AUTOSAR XML (schema 4-1-3)
standard types defined: boolean, sint8, uint16, uint32, uint8, boolean_CompuMethod, boolean_DataConstr, sint8_DataConstr, uint16_DataConstr, uint32_DataConstr, uint8_DataConstr, sint16, sint32
package /MICROSAR/Dem_swc/DataTypes
  5 x impl type:
    Dem_DebounceResetStatusType: compu {0=DEM_DEBOUNCE_STATUS_FREEZE, 1=DEM_DEBOUNCE_STATUS_RESET}, range raw 0..255, implementation-data-type=ImplementationDataTypes/uint8
    Dem_DTCFormatType: compu {0=DEM_DTC_FORMAT_OBD, 1=DEM_DTC_FORMAT_UDS, 2=DEM_DTC_FORMAT_J1939}, range raw 0..2, implementation-data-type=ImplementationDataTypes/uint8
    Dem_EventStatusType:
      compu {0=DEM_EVENT_STATUS_PASSED, 1=DEM_EVENT_STATUS_FAILED, 2=DEM_EVENT_STATUS_PREPASSED, 3=DEM_EVENT_STATUS_PREFAILED, 4=DEM_EVENT_STATUS_FDC_THRESHOLD_REACHED, 5=DEM_EVENT_STATUS_PASSED_CONDITIONS_NOT_FULFILLED, 6=DEM_EVENT_STATUS_FAILED_CONDITIONS_NOT_FULFILLED, 7=DEM_EVENT_STATUS_PREPASSED_CONDITIONS_NOT_FULFILLED, 8=DEM_EVENT_STATUS_PREFAILED_CONDITIONS_NOT_FULFILLED}
      range raw 0..255
      implementation-data-type=ImplementationDataTypes/uint8
    Dem_MaxDataValueType: category=ARRAY, sw-calibration-access=READ-ONLY
      element Dem_MaxDataValueTypeElement: array-size=16, array-size-semantics=FIXED-SIZE, implementation-data-type=ImplementationDataTypes/uint8
    Dem_UdsStatusByteType:
      compu {mask 1: 1=DEM_UDS_STATUS_TF (bit 0: TestFailed), mask 2: 2=DEM_UDS_STATUS_TFTOC (bit 1: TestFailedThisOperationCycle), mask 4: 4=DEM_UDS_STATUS_PDTC (bit 2: PendingDTC), mask 8: 8=DEM_UDS_STATUS_CDTC (bit 3: ConfirmedDTC), mask 16: 16=DEM_UDS_STATUS_TNCSLC (bit 4: TestNotCompletedSinceLastClear), mask 32: 32=DEM_UDS_STATUS_TFSLC (bit 5: TestFailedSinceLastClear), mask 64: 64=DEM_UDS_STATUS_TNCTOC (bit 6: TestNotCompletedThisOperationCycle), mask 128: 128=DEM_UDS_STATUS_WIR (bit 7: WarningIndicatorRequested)}
      range raw 0..255
      implementation-data-type=ImplementationDataTypes/uint8
package /MICROSAR/Dem_swc/Interfaces
  client server interface DiagnosticMonitor: is-service=true, service-kind=DIAGNOSTIC-EVENT-MANAGER
    11 x operation:
      GetDTCOfEvent: possible-error=[DEM_E_NO_DTC_AVAILABLE, DiagnosticMonitor/E_NOT_OK]
        arg DTCFormat: type=Dem_DTCFormatType, direction=IN, server-argument-impl-policy=USE-ARGUMENT-TYPE
        arg DTCOfEvent: type=ImplementationDataTypes/uint32, direction=OUT, server-argument-impl-policy=USE-ARGUMENT-TYPE
      GetEventExtendedDataRecordEx: possible-error=[DEM_BUFFER_TOO_SMALL, DEM_NO_SUCH_ELEMENT, DiagnosticMonitor/E_NOT_OK]
        arg RecordNumber: type=ImplementationDataTypes/uint8, direction=IN, server-argument-impl-policy=USE-ARGUMENT-TYPE
        arg DestBuffer: type=Dem_MaxDataValueType, direction=OUT, server-argument-impl-policy=USE-ARGUMENT-TYPE
        arg BufSize: type=ImplementationDataTypes/uint16, direction=INOUT, server-argument-impl-policy=USE-ARGUMENT-TYPE
      GetEventFailed: possible-error=DiagnosticMonitor/E_NOT_OK
        arg EventFailed: type=ImplementationDataTypes/boolean, direction=OUT, server-argument-impl-policy=USE-ARGUMENT-TYPE
      GetEventFreezeFrameDataEx: possible-error=[DEM_BUFFER_TOO_SMALL, DEM_NO_SUCH_ELEMENT, DiagnosticMonitor/E_NOT_OK]
        4 x arg, all with server-argument-impl-policy=USE-ARGUMENT-TYPE:
          RecordNumber: type=ImplementationDataTypes/uint8, direction=IN
          DataId: type=ImplementationDataTypes/uint16, direction=IN
          DestBuffer: type=Dem_MaxDataValueType, direction=OUT
          BufSize: type=ImplementationDataTypes/uint16, direction=INOUT
      GetEventStatus: possible-error=DiagnosticMonitor/E_NOT_OK
        arg UDSStatusByte: type=Dem_UdsStatusByteType, direction=OUT, server-argument-impl-policy=USE-ARGUMENT-TYPE
      GetEventTested: possible-error=DiagnosticMonitor/E_NOT_OK
        arg EventTested: type=ImplementationDataTypes/boolean, direction=OUT, server-argument-impl-policy=USE-ARGUMENT-TYPE
      GetEventUdsStatus: possible-error=DiagnosticMonitor/E_NOT_OK
        arg UDSStatusByte: type=Dem_UdsStatusByteType, direction=OUT, server-argument-impl-policy=USE-ARGUMENT-TYPE
      GetFaultDetectionCounter: possible-error=[DEM_E_NO_FDC_AVAILABLE, DiagnosticMonitor/E_NOT_OK]
        arg FaultDetectionCounter: type=sint8, direction=OUT, server-argument-impl-policy=USE-ARGUMENT-TYPE
      ResetEventDebounceStatus: possible-error=DiagnosticMonitor/E_NOT_OK
        arg DebounceResetStatus: type=Dem_DebounceResetStatusType, direction=IN, server-argument-impl-policy=USE-ARGUMENT-TYPE
      ResetEventStatus: possible-error=DiagnosticMonitor/E_NOT_OK
      SetEventStatus: possible-error=DiagnosticMonitor/E_NOT_OK
        arg EventStatus: type=Dem_EventStatusType, direction=IN, server-argument-impl-policy=USE-ARGUMENT-TYPE
    5 x error:
      DEM_BUFFER_TOO_SMALL: error-code=21
      DEM_E_NO_DTC_AVAILABLE: error-code=10
      DEM_E_NO_FDC_AVAILABLE: error-code=14
      DEM_NO_SUCH_ELEMENT: error-code=48
      E_NOT_OK: error-code=1
package /SwAddrMethods
  sw addr method CALDATA
package /UAES/ASW/ApplicationDataTypes
  app type Curr_Ampr_u16: category=VALUE, sw-calibration-access=READ-WRITE, compu {phys=raw*0.1; unit A}, range raw 0..65535, unit=A
  app type q1Em6_s_S32: category=VALUE, sw-calibration-access=READ-WRITE, compu {phys=raw*1e-06}, range phys -2147.483648..2147.483647, raw -2147483648..2147483647
package /UAES/ASW/CompuMethods
  compu method CM_boolean: 0=FALSE, 1=TRUE
package /UAES/ASW/DataConstrs
  range DC_sint16: raw -32768..32767
package /UAES/ASW/DataTypeMappingSets
  data type mapping set DTMS_FaultDiag
    data-type-maps:
      application-data-type=Curr_Ampr_u16, implementation-data-type=ImplementationDataTypes/uint16
      application-data-type=q1Em6_s_S32, implementation-data-type=sint32
package /UAES/ASW/ImplementationDataTypes
  4 x impl type, all with category=ARRAY:
    rt_Array_boolean_29
      element rt_Array_boolean_29: array-size=29, array-size-semantics=FIXED-SIZE, implementation-data-type=ImplementationDataTypes/boolean
    rt_Array_uint16_25
      element rt_Array_uint16_25: array-size=25, array-size-semantics=FIXED-SIZE, implementation-data-type=ImplementationDataTypes/uint16
    rt_Array_uint16_29
      element rt_Array_uint16_29: array-size=29, array-size-semantics=FIXED-SIZE, implementation-data-type=ImplementationDataTypes/uint16
    rt_Array_uint8_29
      element rt_Array_uint8_29: array-size=29, array-size-semantics=FIXED-SIZE, implementation-data-type=ImplementationDataTypes/uint8
package /UAES/ASW/PortInterfaces
  7 x client server interface:
    IoHwAb_IoDiagDo
      operation Do_Get: possible-error=IoHwAb_IoDiagDo/E_NOT_OK
        arg id_u16: type=ImplementationDataTypes/uint16, direction=IN, server-argument-impl-policy=USE-ARGUMENT-TYPE
        arg val_u32: type=ImplementationDataTypes/uint32, direction=OUT, server-argument-impl-policy=USE-ARGUMENT-TYPE
      error E_NOT_OK: error-code=1
    IoHwAb_IoDiagPwm
      operation Pwm_Get: possible-error=IoHwAb_IoDiagPwm/E_NOT_OK
        arg id_u16: type=ImplementationDataTypes/uint16, direction=IN, server-argument-impl-policy=USE-ARGUMENT-TYPE
        arg val_u32: type=ImplementationDataTypes/uint32, direction=OUT, server-argument-impl-policy=USE-ARGUMENT-TYPE
      error E_NOT_OK: error-code=1
    IoHwAb_IoSigAdc
      operation Adc_Get: possible-error=IoHwAb_IoSigAdc/E_NOT_OK
        arg id_u16: type=ImplementationDataTypes/uint16, direction=IN, server-argument-impl-policy=USE-ARGUMENT-TYPE
        arg val_s16: type=sint16, direction=OUT, server-argument-impl-policy=USE-ARGUMENT-TYPE
      operation AdcFac_Get: possible-error=IoHwAb_IoSigAdc/E_NOT_OK
        arg id_u16: type=ImplementationDataTypes/uint16, direction=IN, server-argument-impl-policy=USE-ARGUMENT-TYPE
        arg val_s16: type=sint16, direction=OUT, server-argument-impl-policy=USE-ARGUMENT-TYPE
      operation AdcVRMBatt_Get: possible-error=IoHwAb_IoSigAdc/E_NOT_OK
        arg id_u16: type=ImplementationDataTypes/uint16, direction=IN, server-argument-impl-policy=USE-ARGUMENT-TYPE
        arg val_u8: type=ImplementationDataTypes/uint8, direction=OUT, server-argument-impl-policy=USE-ARGUMENT-TYPE
      error E_NOT_OK: error-code=1
    IoHwAb_IoSigDio
      operation Di_Get: possible-error=IoHwAb_IoSigDio/E_NOT_OK
        arg id_u16: type=ImplementationDataTypes/uint16, direction=IN, server-argument-impl-policy=USE-ARGUMENT-TYPE
        arg val_u8: type=ImplementationDataTypes/uint8, direction=OUT, server-argument-impl-policy=USE-ARGUMENT-TYPE
      operation Do_Set: possible-error=IoHwAb_IoSigDio/E_NOT_OK
        arg id_u16: type=ImplementationDataTypes/uint16, direction=IN, server-argument-impl-policy=USE-ARGUMENT-TYPE
        arg val_u8: type=ImplementationDataTypes/uint8, direction=IN, server-argument-impl-policy=USE-ARGUMENT-TYPE
      error E_NOT_OK: error-code=1
    IoHwAb_IoSigPwm
      operation Pwm_SetDuty: possible-error=IoHwAb_IoSigPwm/E_NOT_OK
        arg id_u16: type=ImplementationDataTypes/uint16, direction=IN, server-argument-impl-policy=USE-ARGUMENT-TYPE
        arg duty_u16: type=ImplementationDataTypes/uint16, direction=IN, server-argument-impl-policy=USE-ARGUMENT-TYPE
      operation Pwm_SetPerd: possible-error=IoHwAb_IoSigPwm/E_NOT_OK
        arg id_u16: type=ImplementationDataTypes/uint16, direction=IN, server-argument-impl-policy=USE-ARGUMENT-TYPE
        arg perd_u32: type=ImplementationDataTypes/uint32, direction=IN, server-argument-impl-policy=USE-ARGUMENT-TYPE
      operation Pwm_SetPerdAndDuty: possible-error=IoHwAb_IoSigPwm/E_NOT_OK
        arg id_u16: type=ImplementationDataTypes/uint16, direction=IN, server-argument-impl-policy=USE-ARGUMENT-TYPE
        arg perd_u32: type=ImplementationDataTypes/uint32, direction=IN, server-argument-impl-policy=USE-ARGUMENT-TYPE
        arg duty_u16: type=ImplementationDataTypes/uint16, direction=IN, server-argument-impl-policy=USE-ARGUMENT-TYPE
      error E_NOT_OK: error-code=1
    NMW_tGetAllCurrentComModeRTE
      operation Operation: possible-error=NMW_tGetAllCurrentComModeRTE/NmChannelIndexError
        arg Status: type=ImplementationDataTypes/boolean, direction=OUT, server-argument-impl-policy=USE-ARGUMENT-TYPE
      error NmChannelIndexError: error-code=1
    NMW_tGetCurrentComModeRTE
      operation Operation: possible-error=NMW_tGetCurrentComModeRTE/NmChannelIndexError
        arg ComMChannel: type=ImplementationDataTypes/uint8, direction=IN, server-argument-impl-policy=USE-ARGUMENT-TYPE
        arg ChannelStatus: type=ImplementationDataTypes/boolean, direction=OUT, server-argument-impl-policy=USE-ARGUMENT-TYPE
      error NmChannelIndexError: error-code=1
  57 x sender receiver interface:
    BattU_bVoltEnbPinDiag: invalidation-policy{data-element=BattU_bVoltEnbPinDiag/Val, handle-invalid=DONT-INVALIDATE}
      data Val: sw-calibration-access=READ-ONLY, range raw 0..1, type=ImplementationDataTypes/boolean
    gKL15PwrSply_u32AllowSleep_Local: invalidation-policy{data-element=gKL15PwrSply_u32AllowSleep_Local/Val, handle-invalid=DONT-INVALIDATE}
      data Val: sw-calibration-access=READ-ONLY, range raw 0..4294967295, type=ImplementationDataTypes/uint32
    gKL15PwrSply_u32AllowSleep_NW: invalidation-policy{data-element=gKL15PwrSply_u32AllowSleep_NW/Val, handle-invalid=DONT-INVALIDATE}
      data Val: sw-calibration-access=READ-ONLY, range raw 0..4294967295, type=ImplementationDataTypes/uint32
    gKL15PwrSply_u8Wakeup: invalidation-policy{data-element=gKL15PwrSply_u8Wakeup/Val, handle-invalid=DONT-INVALIDATE}
      data Val: sw-calibration-access=READ-ONLY, range raw 0..255, type=ImplementationDataTypes/uint8
    gPRM_au16OvrCurrDebTime: invalidation-policy{data-element=gPRM_au16OvrCurrDebTime/Val, handle-invalid=DONT-INVALIDATE}
      data Val: sw-calibration-access=READ-ONLY, range raw 0..65535, type=rt_Array_uint16_25
    gPRM_au16OvrCurrThres: invalidation-policy{data-element=gPRM_au16OvrCurrThres/Val, handle-invalid=DONT-INVALIDATE}
      data Val: sw-calibration-access=READ-ONLY, range raw 0..65535, type=rt_Array_uint16_25
    gPRM_u8VehRLCM: invalidation-policy{data-element=gPRM_u8VehRLCM/Val, handle-invalid=DONT-INVALIDATE}
      data Val: sw-calibration-access=READ-ONLY, range raw 0..255, type=ImplementationDataTypes/uint8
    gVRM_u16BatteryVolt_mv: invalidation-policy{data-element=gVRM_u16BatteryVolt_mv/Val, handle-invalid=DONT-INVALIDATE}
      data Val: sw-calibration-access=READ-ONLY, type=ImplementationDataTypes/uint16
    KL15PwrSply_bAMPPowerTrigUds: invalidation-policy{data-element=KL15PwrSply_bAMPPowerTrigUds/Val, handle-invalid=DONT-INVALIDATE}
      data Val: sw-calibration-access=READ-ONLY, range raw 0..1, type=ImplementationDataTypes/boolean
    KL15PwrSply_bInverterPowerTrigUds: invalidation-policy{data-element=KL15PwrSply_bInverterPowerTrigUds/Val, handle-invalid=DONT-INVALIDATE}
      data Val: sw-calibration-access=READ-ONLY, range raw 0..1, type=ImplementationDataTypes/boolean
    KL15PwrSply_bKL15T1PowerTrigUds: invalidation-policy{data-element=KL15PwrSply_bKL15T1PowerTrigUds/Val, handle-invalid=DONT-INVALIDATE}
      data Val: sw-calibration-access=READ-ONLY, range raw 0..1, type=ImplementationDataTypes/boolean
    KL15PwrSply_bKL15T2PowerTrigUds: invalidation-policy{data-element=KL15PwrSply_bKL15T2PowerTrigUds/Val, handle-invalid=DONT-INVALIDATE}
      data Val: sw-calibration-access=READ-ONLY, range raw 0..1, type=ImplementationDataTypes/boolean
    KL15PwrSply_bPCUPowerTrigUds: invalidation-policy{data-element=KL15PwrSply_bPCUPowerTrigUds/Val, handle-invalid=DONT-INVALIDATE}
      data Val: sw-calibration-access=READ-ONLY, range raw 0..1, type=ImplementationDataTypes/boolean
    KL15PwrSply_bRear12VPowerTrigUds: invalidation-policy{data-element=KL15PwrSply_bRear12VPowerTrigUds/Val, handle-invalid=DONT-INVALIDATE}
      data Val: sw-calibration-access=READ-ONLY, range raw 0..1, type=ImplementationDataTypes/boolean
    KL15PwrSply_bRearBlowerPowerTrigUds: invalidation-policy{data-element=KL15PwrSply_bRearBlowerPowerTrigUds/Val, handle-invalid=DONT-INVALIDATE}
      data Val: sw-calibration-access=READ-ONLY, range raw 0..1, type=ImplementationDataTypes/boolean
    KL15PwrSply_bRearCtrlPanelPowerTrigUds: invalidation-policy{data-element=KL15PwrSply_bRearCtrlPanelPowerTrigUds/Val, handle-invalid=DONT-INVALIDATE}
      data Val: sw-calibration-access=READ-ONLY, range raw 0..1, type=ImplementationDataTypes/boolean
    KL15PwrSply_bRearEOPPowerTrigUds: invalidation-policy{data-element=KL15PwrSply_bRearEOPPowerTrigUds/Val, handle-invalid=DONT-INVALIDATE}
      data Val: sw-calibration-access=READ-ONLY, range raw 0..1, type=ImplementationDataTypes/boolean
    KL15PwrSply_bRearMotorPowerTrigUds: invalidation-policy{data-element=KL15PwrSply_bRearMotorPowerTrigUds/Val, handle-invalid=DONT-INVALIDATE}
      data Val: sw-calibration-access=READ-ONLY, range raw 0..1, type=ImplementationDataTypes/boolean
    KL15PwrSply_bRearRadarPowerTrigUds: invalidation-policy{data-element=KL15PwrSply_bRearRadarPowerTrigUds/Val, handle-invalid=DONT-INVALIDATE}
      data Val: sw-calibration-access=READ-ONLY, range raw 0..1, type=ImplementationDataTypes/boolean
    KL15PwrSply_bRLALampCtlUnitPowerTrigUds: invalidation-policy{data-element=KL15PwrSply_bRLALampCtlUnitPowerTrigUds/Val, handle-invalid=DONT-INVALIDATE}
      data Val: sw-calibration-access=READ-ONLY, range raw 0..1, type=ImplementationDataTypes/boolean
    KL15PwrSply_bRLBLampCtlUnitPowerTrigUds: invalidation-policy{data-element=KL15PwrSply_bRLBLampCtlUnitPowerTrigUds/Val, handle-invalid=DONT-INVALIDATE}
      data Val: sw-calibration-access=READ-ONLY, range raw 0..1, type=ImplementationDataTypes/boolean
    KL15PwrSply_bRMPowerTrigUds: invalidation-policy{data-element=KL15PwrSply_bRMPowerTrigUds/Val, handle-invalid=DONT-INVALIDATE}
      data Val: sw-calibration-access=READ-ONLY, range raw 0..1, type=ImplementationDataTypes/boolean
    KL15PwrSply_bRRALampCtlUnitPowerTrigUds: invalidation-policy{data-element=KL15PwrSply_bRRALampCtlUnitPowerTrigUds/Val, handle-invalid=DONT-INVALIDATE}
      data Val: sw-calibration-access=READ-ONLY, range raw 0..1, type=ImplementationDataTypes/boolean
    KL15PwrSply_bRRBLampCtlUnitPowerTrigUds: invalidation-policy{data-element=KL15PwrSply_bRRBLampCtlUnitPowerTrigUds/Val, handle-invalid=DONT-INVALIDATE}
      data Val: sw-calibration-access=READ-ONLY, range raw 0..1, type=ImplementationDataTypes/boolean
    KL15PwrSply_u8stAMPPowerUds: invalidation-policy{data-element=KL15PwrSply_u8stAMPPowerUds/Val, handle-invalid=DONT-INVALIDATE}
      data Val: sw-calibration-access=READ-ONLY, range raw 0..255, type=ImplementationDataTypes/uint8
    KL15PwrSply_u8stInverterPowerUds: invalidation-policy{data-element=KL15PwrSply_u8stInverterPowerUds/Val, handle-invalid=DONT-INVALIDATE}
      data Val: sw-calibration-access=READ-ONLY, range raw 0..255, type=ImplementationDataTypes/uint8
    KL15PwrSply_u8stKL15T1PowerUds: invalidation-policy{data-element=KL15PwrSply_u8stKL15T1PowerUds/Val, handle-invalid=DONT-INVALIDATE}
      data Val: sw-calibration-access=READ-ONLY, range raw 0..255, type=ImplementationDataTypes/uint8
    KL15PwrSply_u8stKL15T2PowerUds: invalidation-policy{data-element=KL15PwrSply_u8stKL15T2PowerUds/Val, handle-invalid=DONT-INVALIDATE}
      data Val: sw-calibration-access=READ-ONLY, range raw 0..255, type=ImplementationDataTypes/uint8
    KL15PwrSply_u8stPCUPowerUds: invalidation-policy{data-element=KL15PwrSply_u8stPCUPowerUds/Val, handle-invalid=DONT-INVALIDATE}
      data Val: sw-calibration-access=READ-ONLY, range raw 0..255, type=ImplementationDataTypes/uint8
    KL15PwrSply_u8stRear12VPowerUds: invalidation-policy{data-element=KL15PwrSply_u8stRear12VPowerUds/Val, handle-invalid=DONT-INVALIDATE}
      data Val: sw-calibration-access=READ-ONLY, range raw 0..255, type=ImplementationDataTypes/uint8
    KL15PwrSply_u8stRearBlowerPowerUds: invalidation-policy{data-element=KL15PwrSply_u8stRearBlowerPowerUds/Val, handle-invalid=DONT-INVALIDATE}
      data Val: sw-calibration-access=READ-ONLY, range raw 0..255, type=ImplementationDataTypes/uint8
    KL15PwrSply_u8stRearCtrlPanelPowerUds: invalidation-policy{data-element=KL15PwrSply_u8stRearCtrlPanelPowerUds/Val, handle-invalid=DONT-INVALIDATE}
      data Val: sw-calibration-access=READ-ONLY, range raw 0..255, type=ImplementationDataTypes/uint8
    KL15PwrSply_u8stRearEOPPowerUds: invalidation-policy{data-element=KL15PwrSply_u8stRearEOPPowerUds/Val, handle-invalid=DONT-INVALIDATE}
      data Val: sw-calibration-access=READ-ONLY, range raw 0..255, type=ImplementationDataTypes/uint8
    KL15PwrSply_u8stRearMotorPowerUds: invalidation-policy{data-element=KL15PwrSply_u8stRearMotorPowerUds/Val, handle-invalid=DONT-INVALIDATE}
      data Val: sw-calibration-access=READ-ONLY, range raw 0..255, type=ImplementationDataTypes/uint8
    KL15PwrSply_u8stRearRadarPowerUds: invalidation-policy{data-element=KL15PwrSply_u8stRearRadarPowerUds/Val, handle-invalid=DONT-INVALIDATE}
      data Val: sw-calibration-access=READ-ONLY, range raw 0..255, type=ImplementationDataTypes/uint8
    KL15PwrSply_u8stRLALampCtlUnitPowerUds: invalidation-policy{data-element=KL15PwrSply_u8stRLALampCtlUnitPowerUds/Val, handle-invalid=DONT-INVALIDATE}
      data Val: sw-calibration-access=READ-ONLY, range raw 0..255, type=ImplementationDataTypes/uint8
    KL15PwrSply_u8stRLBLampCtlUnitPowerUds: invalidation-policy{data-element=KL15PwrSply_u8stRLBLampCtlUnitPowerUds/Val, handle-invalid=DONT-INVALIDATE}
      data Val: sw-calibration-access=READ-ONLY, range raw 0..255, type=ImplementationDataTypes/uint8
    KL15PwrSply_u8stRMPowerUds: invalidation-policy{data-element=KL15PwrSply_u8stRMPowerUds/Val, handle-invalid=DONT-INVALIDATE}
      data Val: sw-calibration-access=READ-ONLY, range raw 0..255, type=ImplementationDataTypes/uint8
    KL15PwrSply_u8stRRALampCtlUnitPowerUds: invalidation-policy{data-element=KL15PwrSply_u8stRRALampCtlUnitPowerUds/Val, handle-invalid=DONT-INVALIDATE}
      data Val: sw-calibration-access=READ-ONLY, range raw 0..255, type=ImplementationDataTypes/uint8
    KL15PwrSply_u8stRRBLampCtlUnitPowerUds: invalidation-policy{data-element=KL15PwrSply_u8stRRBLampCtlUnitPowerUds/Val, handle-invalid=DONT-INVALIDATE}
      data Val: sw-calibration-access=READ-ONLY, range raw 0..255, type=ImplementationDataTypes/uint8
    OilPmp_stReqIn: invalidation-policy{data-element=OilPmp_stReqIn/Val, handle-invalid=DONT-INVALIDATE}
      data Val: sw-calibration-access=READ-ONLY, type=ImplementationDataTypes/uint8
    PwrSply_abPwrSt: invalidation-policy{data-element=PwrSply_abPwrSt/Val, handle-invalid=DONT-INVALIDATE}
      data Val: sw-calibration-access=READ-ONLY, range raw 0..1, type=rt_Array_boolean_29
    PwrSply_au16PwrCurr: invalidation-policy{data-element=PwrSply_au16PwrCurr/Val, handle-invalid=DONT-INVALIDATE}
      data Val: sw-calibration-access=READ-ONLY, range raw 0..65535, type=rt_Array_uint16_29
    PwrSply_au8CoornReq: invalidation-policy{data-element=PwrSply_au8CoornReq/Val, handle-invalid=DONT-INVALIDATE}
      data Val: sw-calibration-access=READ-ONLY, type=rt_Array_uint8_29
    PwrSply_au8PwrFaultSt: invalidation-policy{data-element=PwrSply_au8PwrFaultSt/Val, handle-invalid=DONT-INVALIDATE}
      data Val: sw-calibration-access=READ-ONLY, type=rt_Array_uint8_29
    PwrSply_au8PwrSup: invalidation-policy{data-element=PwrSply_au8PwrSup/Val, handle-invalid=DONT-INVALIDATE}
      data Val: sw-calibration-access=READ-ONLY, type=rt_Array_uint8_29
    PwrSply_bCCULostComm: invalidation-policy{data-element=PwrSply_bCCULostComm/Val, handle-invalid=DONT-INVALIDATE}
      data Val: sw-calibration-access=READ-ONLY, range raw 0..1, type=ImplementationDataTypes/boolean
    PwrSply_bNetSleepFlag: invalidation-policy{data-element=PwrSply_bNetSleepFlag/Val, handle-invalid=DONT-INVALIDATE}
      data Val: sw-calibration-access=READ-ONLY, range raw 0..1, type=ImplementationDataTypes/boolean
    PwrSply_bPositionLightCtrlCmd01: invalidation-policy{data-element=PwrSply_bPositionLightCtrlCmd01/Val, handle-invalid=DONT-INVALIDATE}
      data Val: sw-calibration-access=READ-ONLY, type=ImplementationDataTypes/boolean
    PwrSply_bPositionLightCtrlCmd02: invalidation-policy{data-element=PwrSply_bPositionLightCtrlCmd02/Val, handle-invalid=DONT-INVALIDATE}
      data Val: sw-calibration-access=READ-ONLY, type=ImplementationDataTypes/boolean
    PwrSply_bPositionLightCtrlCmd03: invalidation-policy{data-element=PwrSply_bPositionLightCtrlCmd03/Val, handle-invalid=DONT-INVALIDATE}
      data Val: sw-calibration-access=READ-ONLY, type=ImplementationDataTypes/boolean
    PwrSply_bPositionLightCtrlCmd04: invalidation-policy{data-element=PwrSply_bPositionLightCtrlCmd04/Val, handle-invalid=DONT-INVALIDATE}
      data Val: sw-calibration-access=READ-ONLY, type=ImplementationDataTypes/boolean
    PwrSply_bPositionLightTimingOFFEnableCfg: invalidation-policy{data-element=PwrSply_bPositionLightTimingOFFEnableCfg/Val, handle-invalid=DONT-INVALIDATE}
      data Val: sw-calibration-access=READ-ONLY, type=ImplementationDataTypes/boolean
    PwrSply_bVehSpdTkOvr: invalidation-policy{data-element=PwrSply_bVehSpdTkOvr/Val, handle-invalid=DONT-INVALIDATE}
      data Val: sw-calibration-access=READ-ONLY, range raw 0..1, type=ImplementationDataTypes/boolean
    PwrSply_u8UMM_UsageModeSt: invalidation-policy{data-element=PwrSply_u8UMM_UsageModeSt/Val, handle-invalid=DONT-INVALIDATE}
      data Val: sw-calibration-access=READ-ONLY, range raw 0..255, type=ImplementationDataTypes/uint8
    PwrSply_u8VehicleTypeCfg: invalidation-policy{data-element=PwrSply_u8VehicleTypeCfg/Val, handle-invalid=DONT-INVALIDATE}
      data Val: sw-calibration-access=READ-ONLY, range raw 0..255, type=ImplementationDataTypes/uint8
    PwrSply_u8VMM_OTAModeSt: invalidation-policy{data-element=PwrSply_u8VMM_OTAModeSt/Val, handle-invalid=DONT-INVALIDATE}
      data Val: sw-calibration-access=READ-ONLY, range raw 0..255, type=ImplementationDataTypes/uint8
package /UAES/ASW/SwAddrMethods
  sw addr method CALDATA
package /UAES/ASW/SwComponentTypes
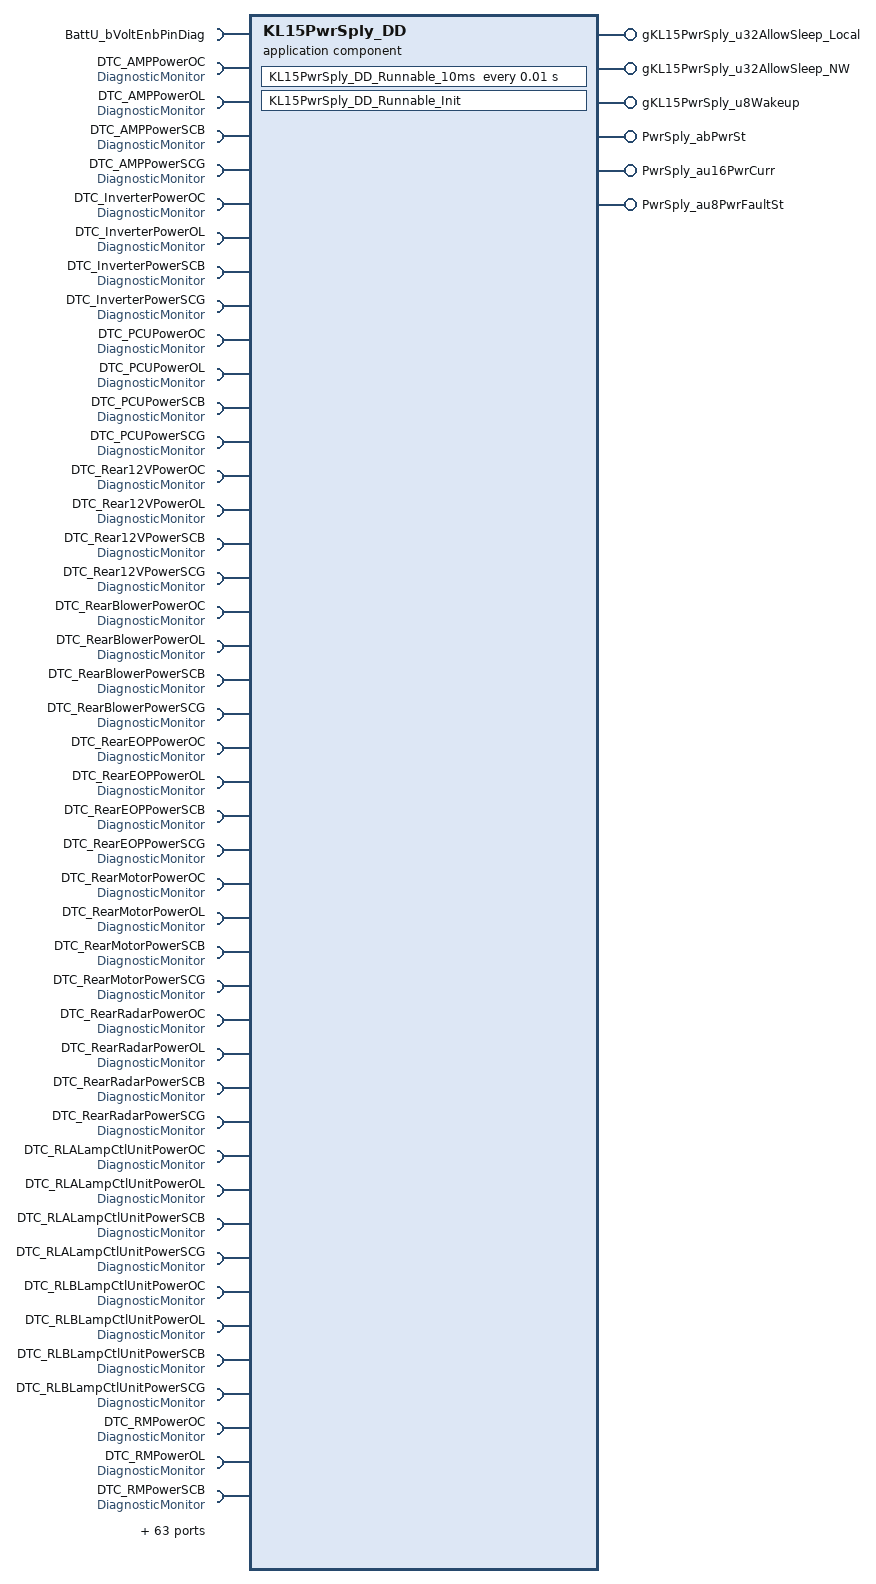
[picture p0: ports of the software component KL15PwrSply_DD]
  application sw component type KL15PwrSply_DD
    6 x provide port:
      gKL15PwrSply_u32AllowSleep_Local: nonqueued-sender-com-spec{data-element=gKL15PwrSply_u32AllowSleep_Local/Val, init-value=0}, provided-interface=gKL15PwrSply_u32AllowSleep_Local
      gKL15PwrSply_u32AllowSleep_NW: nonqueued-sender-com-spec{data-element=gKL15PwrSply_u32AllowSleep_NW/Val, init-value=0}, provided-interface=gKL15PwrSply_u32AllowSleep_NW
      gKL15PwrSply_u8Wakeup: nonqueued-sender-com-spec{data-element=gKL15PwrSply_u8Wakeup/Val, init-value=0}, provided-interface=gKL15PwrSply_u8Wakeup
      PwrSply_abPwrSt: nonqueued-sender-com-spec{data-element=PwrSply_abPwrSt/Val, init-value=29 x 0}, provided-interface=PwrSply_abPwrSt
      PwrSply_au16PwrCurr: nonqueued-sender-com-spec{data-element=PwrSply_au16PwrCurr/Val, init-value=29 x 0}, provided-interface=PwrSply_au16PwrCurr
      PwrSply_au8PwrFaultSt: nonqueued-sender-com-spec{data-element=PwrSply_au8PwrFaultSt/Val, init-value=29 x 0}, provided-interface=PwrSply_au8PwrFaultSt
    110 x require port:
      BattU_bVoltEnbPinDiag: nonqueued-receiver-com-spec{data-element=BattU_bVoltEnbPinDiag/Val, filter=data-filter-type=ALWAYS, init-value=0}, required-interface=BattU_bVoltEnbPinDiag
      DTC_AMPPowerOC: required-interface=DiagnosticMonitor
        required-com-specs:
          GetDTCOfEvent
          GetEventExtendedDataRecordEx
          GetEventFailed
          GetEventFreezeFrameDataEx
          GetEventStatus
          GetEventTested
          GetEventUdsStatus
          GetFaultDetectionCounter
          ResetEventDebounceStatus
          ResetEventStatus
          SetEventStatus
      DTC_AMPPowerOL: required-interface=DiagnosticMonitor
        required-com-specs:
          GetDTCOfEvent
          GetEventExtendedDataRecordEx
          GetEventFailed
          GetEventFreezeFrameDataEx
          GetEventStatus
          GetEventTested
          GetEventUdsStatus
          GetFaultDetectionCounter
          ResetEventDebounceStatus
          ResetEventStatus
          SetEventStatus
      DTC_AMPPowerSCB: required-interface=DiagnosticMonitor
        required-com-specs:
          GetDTCOfEvent
          GetEventExtendedDataRecordEx
          GetEventFailed
          GetEventFreezeFrameDataEx
          GetEventStatus
          GetEventTested
          GetEventUdsStatus
          GetFaultDetectionCounter
          ResetEventDebounceStatus
          ResetEventStatus
          SetEventStatus
      DTC_AMPPowerSCG: required-interface=DiagnosticMonitor
        required-com-specs:
          GetDTCOfEvent
          GetEventExtendedDataRecordEx
          GetEventFailed
          GetEventFreezeFrameDataEx
          GetEventStatus
          GetEventTested
          GetEventUdsStatus
          GetFaultDetectionCounter
          ResetEventDebounceStatus
          ResetEventStatus
          SetEventStatus
      DTC_InverterPowerOC: required-interface=DiagnosticMonitor
        required-com-specs:
          GetDTCOfEvent
          GetEventExtendedDataRecordEx
          GetEventFailed
          GetEventFreezeFrameDataEx
          GetEventStatus
          GetEventTested
          GetEventUdsStatus
          GetFaultDetectionCounter
          ResetEventDebounceStatus
          ResetEventStatus
          SetEventStatus
      DTC_InverterPowerOL: required-interface=DiagnosticMonitor
        required-com-specs:
          GetDTCOfEvent
          GetEventExtendedDataRecordEx
          GetEventFailed
          GetEventFreezeFrameDataEx
          GetEventStatus
          GetEventTested
          GetEventUdsStatus
          GetFaultDetectionCounter
          ResetEventDebounceStatus
          ResetEventStatus
          SetEventStatus
      DTC_InverterPowerSCB: required-interface=DiagnosticMonitor
        required-com-specs:
          GetDTCOfEvent
          GetEventExtendedDataRecordEx
          GetEventFailed
          GetEventFreezeFrameDataEx
          GetEventStatus
          GetEventTested
          GetEventUdsStatus
          GetFaultDetectionCounter
          ResetEventDebounceStatus
          ResetEventStatus
          SetEventStatus
      DTC_InverterPowerSCG: required-interface=DiagnosticMonitor
        required-com-specs:
          GetDTCOfEvent
          GetEventExtendedDataRecordEx
          GetEventFailed
          GetEventFreezeFrameDataEx
          GetEventStatus
          GetEventTested
          GetEventUdsStatus
          GetFaultDetectionCounter
          ResetEventDebounceStatus
          ResetEventStatus
          SetEventStatus
      DTC_PCUPowerOC: required-interface=DiagnosticMonitor
        required-com-specs:
          GetDTCOfEvent
          GetEventExtendedDataRecordEx
          GetEventFailed
          GetEventFreezeFrameDataEx
          GetEventStatus
          GetEventTested
          GetEventUdsStatus
          GetFaultDetectionCounter
          ResetEventDebounceStatus
          ResetEventStatus
          SetEventStatus
      DTC_PCUPowerOL: required-interface=DiagnosticMonitor
        required-com-specs:
          GetDTCOfEvent
          GetEventExtendedDataRecordEx
          GetEventFailed
          GetEventFreezeFrameDataEx
          GetEventStatus
          GetEventTested
          GetEventUdsStatus
          GetFaultDetectionCounter
          ResetEventDebounceStatus
          ResetEventStatus
          SetEventStatus
      DTC_PCUPowerSCB: required-interface=DiagnosticMonitor
        required-com-specs:
          GetDTCOfEvent
          GetEventExtendedDataRecordEx
          GetEventFailed
          GetEventFreezeFrameDataEx
          GetEventStatus
          GetEventTested
          GetEventUdsStatus
          GetFaultDetectionCounter
          ResetEventDebounceStatus
          ResetEventStatus
          SetEventStatus
      DTC_PCUPowerSCG: required-interface=DiagnosticMonitor
        required-com-specs:
          GetDTCOfEvent
          GetEventExtendedDataRecordEx
          GetEventFailed
          GetEventFreezeFrameDataEx
          GetEventStatus
          GetEventTested
          GetEventUdsStatus
          GetFaultDetectionCounter
          ResetEventDebounceStatus
          ResetEventStatus
          SetEventStatus
      DTC_Rear12VPowerOC: required-interface=DiagnosticMonitor
        required-com-specs:
          GetDTCOfEvent
          GetEventExtendedDataRecordEx
          GetEventFailed
          GetEventFreezeFrameDataEx
          GetEventStatus
          GetEventTested
          GetEventUdsStatus
          GetFaultDetectionCounter
          ResetEventDebounceStatus
          ResetEventStatus
          SetEventStatus
      DTC_Rear12VPowerOL: required-interface=DiagnosticMonitor
        required-com-specs:
          GetDTCOfEvent
          GetEventExtendedDataRecordEx
          GetEventFailed
          GetEventFreezeFrameDataEx
          GetEventStatus
          GetEventTested
          GetEventUdsStatus
          GetFaultDetectionCounter
          ResetEventDebounceStatus
          ResetEventStatus
          SetEventStatus
      DTC_Rear12VPowerSCB: required-interface=DiagnosticMonitor
        required-com-specs:
          GetDTCOfEvent
          GetEventExtendedDataRecordEx
          GetEventFailed
          GetEventFreezeFrameDataEx
          GetEventStatus
          GetEventTested
          GetEventUdsStatus
          GetFaultDetectionCounter
          ResetEventDebounceStatus
          ResetEventStatus
          SetEventStatus
      DTC_Rear12VPowerSCG: required-interface=DiagnosticMonitor
        required-com-specs:
          GetDTCOfEvent
          GetEventExtendedDataRecordEx
          GetEventFailed
          GetEventFreezeFrameDataEx
          GetEventStatus
          GetEventTested
          GetEventUdsStatus
          GetFaultDetectionCounter
          ResetEventDebounceStatus
          ResetEventStatus
          SetEventStatus
      DTC_RearBlowerPowerOC: required-interface=DiagnosticMonitor
        required-com-specs:
          GetDTCOfEvent
          GetEventExtendedDataRecordEx
          GetEventFailed
          GetEventFreezeFrameDataEx
          GetEventStatus
          GetEventTested
          GetEventUdsStatus
          GetFaultDetectionCounter
          ResetEventDebounceStatus
          ResetEventStatus
          SetEventStatus
      DTC_RearBlowerPowerOL: required-interface=DiagnosticMonitor
        required-com-specs:
          GetDTCOfEvent
          GetEventExtendedDataRecordEx
          GetEventFailed
          GetEventFreezeFrameDataEx
          GetEventStatus
          GetEventTested
          GetEventUdsStatus
          GetFaultDetectionCounter
          ResetEventDebounceStatus
          ResetEventStatus
          SetEventStatus
      DTC_RearBlowerPowerSCB: required-interface=DiagnosticMonitor
        required-com-specs:
          GetDTCOfEvent
          GetEventExtendedDataRecordEx
          GetEventFailed
          GetEventFreezeFrameDataEx
          GetEventStatus
          GetEventTested
          GetEventUdsStatus
          GetFaultDetectionCounter
          ResetEventDebounceStatus
          ResetEventStatus
          SetEventStatus
      DTC_RearBlowerPowerSCG: required-interface=DiagnosticMonitor
        required-com-specs:
          GetDTCOfEvent
          GetEventExtendedDataRecordEx
          GetEventFailed
          GetEventFreezeFrameDataEx
          GetEventStatus
          GetEventTested
          GetEventUdsStatus
          GetFaultDetectionCounter
          ResetEventDebounceStatus
          ResetEventStatus
          SetEventStatus
      DTC_RearEOPPowerOC: required-interface=DiagnosticMonitor
        required-com-specs:
          GetDTCOfEvent
          GetEventExtendedDataRecordEx
          GetEventFailed
          GetEventFreezeFrameDataEx
          GetEventStatus
          GetEventTested
          GetEventUdsStatus
          GetFaultDetectionCounter
          ResetEventDebounceStatus
          ResetEventStatus
          SetEventStatus
      DTC_RearEOPPowerOL: required-interface=DiagnosticMonitor
        required-com-specs:
          GetDTCOfEvent
          GetEventExtendedDataRecordEx
          GetEventFailed
          GetEventFreezeFrameDataEx
          GetEventStatus
          GetEventTested
          GetEventUdsStatus
          GetFaultDetectionCounter
          ResetEventDebounceStatus
          ResetEventStatus
          SetEventStatus
      DTC_RearEOPPowerSCB: required-interface=DiagnosticMonitor
        required-com-specs:
          GetDTCOfEvent
          GetEventExtendedDataRecordEx
          GetEventFailed
          GetEventFreezeFrameDataEx
          GetEventStatus
          GetEventTested
          GetEventUdsStatus
          GetFaultDetectionCounter
          ResetEventDebounceStatus
          ResetEventStatus
          SetEventStatus
      DTC_RearEOPPowerSCG: required-interface=DiagnosticMonitor
        required-com-specs:
          GetDTCOfEvent
          GetEventExtendedDataRecordEx
          GetEventFailed
          GetEventFreezeFrameDataEx
          GetEventStatus
          GetEventTested
          GetEventUdsStatus
          GetFaultDetectionCounter
          ResetEventDebounceStatus
          ResetEventStatus
          SetEventStatus
      DTC_RearMotorPowerOC: required-interface=DiagnosticMonitor
        required-com-specs:
          GetDTCOfEvent
          GetEventExtendedDataRecordEx
          GetEventFailed
          GetEventFreezeFrameDataEx
          GetEventStatus
          GetEventTested
          GetEventUdsStatus
          GetFaultDetectionCounter
          ResetEventDebounceStatus
          ResetEventStatus
          SetEventStatus
      DTC_RearMotorPowerOL: required-interface=DiagnosticMonitor
        required-com-specs:
          GetDTCOfEvent
          GetEventExtendedDataRecordEx
          GetEventFailed
          GetEventFreezeFrameDataEx
          GetEventStatus
          GetEventTested
          GetEventUdsStatus
          GetFaultDetectionCounter
          ResetEventDebounceStatus
          ResetEventStatus
          SetEventStatus
      DTC_RearMotorPowerSCB: required-interface=DiagnosticMonitor
        required-com-specs:
          GetDTCOfEvent
          GetEventExtendedDataRecordEx
          GetEventFailed
          GetEventFreezeFrameDataEx
          GetEventStatus
          GetEventTested
          GetEventUdsStatus
          GetFaultDetectionCounter
          ResetEventDebounceStatus
          ResetEventStatus
          SetEventStatus
      DTC_RearMotorPowerSCG: required-interface=DiagnosticMonitor
        required-com-specs:
          GetDTCOfEvent
          GetEventExtendedDataRecordEx
          GetEventFailed
          GetEventFreezeFrameDataEx
          GetEventStatus
          GetEventTested
          GetEventUdsStatus
          GetFaultDetectionCounter
          ResetEventDebounceStatus
          ResetEventStatus
          SetEventStatus
      DTC_RearRadarPowerOC: required-interface=DiagnosticMonitor
        required-com-specs:
          GetDTCOfEvent
          GetEventExtendedDataRecordEx
          GetEventFailed
          GetEventFreezeFrameDataEx
          GetEventStatus
          GetEventTested
          GetEventUdsStatus
          GetFaultDetectionCounter
          ResetEventDebounceStatus
          ResetEventStatus
          SetEventStatus
      DTC_RearRadarPowerOL: required-interface=DiagnosticMonitor
        required-com-specs:
          GetDTCOfEvent
          GetEventExtendedDataRecordEx
          GetEventFailed
          GetEventFreezeFrameDataEx
          GetEventStatus
          GetEventTested
          GetEventUdsStatus
          GetFaultDetectionCounter
          ResetEventDebounceStatus
          ResetEventStatus
          SetEventStatus
      DTC_RearRadarPowerSCB: required-interface=DiagnosticMonitor
        required-com-specs:
          GetDTCOfEvent
          GetEventExtendedDataRecordEx
          GetEventFailed
          GetEventFreezeFrameDataEx
          GetEventStatus
          GetEventTested
          GetEventUdsStatus
          GetFaultDetectionCounter
          ResetEventDebounceStatus
          ResetEventStatus
          SetEventStatus
      DTC_RearRadarPowerSCG: required-interface=DiagnosticMonitor
        required-com-specs:
          GetDTCOfEvent
          GetEventExtendedDataRecordEx
          GetEventFailed
          GetEventFreezeFrameDataEx
          GetEventStatus
          GetEventTested
          GetEventUdsStatus
          GetFaultDetectionCounter
          ResetEventDebounceStatus
          ResetEventStatus
          SetEventStatus
      DTC_RLALampCtlUnitPowerOC: required-interface=DiagnosticMonitor
        required-com-specs:
          GetDTCOfEvent
          GetEventExtendedDataRecordEx
          GetEventFailed
          GetEventFreezeFrameDataEx
          GetEventStatus
          GetEventTested
          GetEventUdsStatus
          GetFaultDetectionCounter
          ResetEventDebounceStatus
          ResetEventStatus
          SetEventStatus
      DTC_RLALampCtlUnitPowerOL: required-interface=DiagnosticMonitor
        required-com-specs:
          GetDTCOfEvent
          GetEventExtendedDataRecordEx
          GetEventFailed
          GetEventFreezeFrameDataEx
          GetEventStatus
          GetEventTested
          GetEventUdsStatus
          GetFaultDetectionCounter
          ResetEventDebounceStatus
          ResetEventStatus
          SetEventStatus
      DTC_RLALampCtlUnitPowerSCB: required-interface=DiagnosticMonitor
        required-com-specs:
          GetDTCOfEvent
          GetEventExtendedDataRecordEx
          GetEventFailed
          GetEventFreezeFrameDataEx
          GetEventStatus
          GetEventTested
          GetEventUdsStatus
          GetFaultDetectionCounter
          ResetEventDebounceStatus
          ResetEventStatus
          SetEventStatus
      DTC_RLALampCtlUnitPowerSCG: required-interface=DiagnosticMonitor
        required-com-specs:
          GetDTCOfEvent
          GetEventExtendedDataRecordEx
          GetEventFailed
          GetEventFreezeFrameDataEx
          GetEventStatus
          GetEventTested
          GetEventUdsStatus
          GetFaultDetectionCounter
          ResetEventDebounceStatus
          ResetEventStatus
          SetEventStatus
      DTC_RLBLampCtlUnitPowerOC: required-interface=DiagnosticMonitor
        required-com-specs:
          GetDTCOfEvent
          GetEventExtendedDataRecordEx
          GetEventFailed
          GetEventFreezeFrameDataEx
          GetEventStatus
          GetEventTested
          GetEventUdsStatus
          GetFaultDetectionCounter
          ResetEventDebounceStatus
          ResetEventStatus
          SetEventStatus
      DTC_RLBLampCtlUnitPowerOL: required-interface=DiagnosticMonitor
        required-com-specs:
          GetDTCOfEvent
          GetEventExtendedDataRecordEx
          GetEventFailed
          GetEventFreezeFrameDataEx
          GetEventStatus
          GetEventTested
          GetEventUdsStatus
          GetFaultDetectionCounter
          ResetEventDebounceStatus
          ResetEventStatus
          SetEventStatus
      DTC_RLBLampCtlUnitPowerSCB: required-interface=DiagnosticMonitor
        required-com-specs:
          GetDTCOfEvent
          GetEventExtendedDataRecordEx
          GetEventFailed
          GetEventFreezeFrameDataEx
          GetEventStatus
          GetEventTested
          GetEventUdsStatus
          GetFaultDetectionCounter
          ResetEventDebounceStatus
          ResetEventStatus
          SetEventStatus
      DTC_RLBLampCtlUnitPowerSCG: required-interface=DiagnosticMonitor
        required-com-specs:
          GetDTCOfEvent
          GetEventExtendedDataRecordEx
          GetEventFailed
          GetEventFreezeFrameDataEx
          GetEventStatus
          GetEventTested
          GetEventUdsStatus
          GetFaultDetectionCounter
          ResetEventDebounceStatus
          ResetEventStatus
          SetEventStatus
      DTC_RMPowerOC: required-interface=DiagnosticMonitor
        required-com-specs:
          GetDTCOfEvent
          GetEventExtendedDataRecordEx
          GetEventFailed
          GetEventFreezeFrameDataEx
          GetEventStatus
          GetEventTested
          GetEventUdsStatus
          GetFaultDetectionCounter
          ResetEventDebounceStatus
          ResetEventStatus
          SetEventStatus
      DTC_RMPowerOL: required-interface=DiagnosticMonitor
        required-com-specs:
          GetDTCOfEvent
          GetEventExtendedDataRecordEx
          GetEventFailed
          GetEventFreezeFrameDataEx
          GetEventStatus
          GetEventTested
          GetEventUdsStatus
          GetFaultDetectionCounter
          ResetEventDebounceStatus
          ResetEventStatus
          SetEventStatus
      DTC_RMPowerSCB: required-interface=DiagnosticMonitor
        required-com-specs:
          GetDTCOfEvent
          GetEventExtendedDataRecordEx
          GetEventFailed
          GetEventFreezeFrameDataEx
          GetEventStatus
          GetEventTested
          GetEventUdsStatus
          GetFaultDetectionCounter
          ResetEventDebounceStatus
          ResetEventStatus
          SetEventStatus
      DTC_RMPowerSCG: required-interface=DiagnosticMonitor
        required-com-specs:
          GetDTCOfEvent
          GetEventExtendedDataRecordEx
          GetEventFailed
          GetEventFreezeFrameDataEx
          GetEventStatus
          GetEventTested
          GetEventUdsStatus
          GetFaultDetectionCounter
          ResetEventDebounceStatus
          ResetEventStatus
          SetEventStatus
      DTC_RRALampCtlUnitPowerOC: required-interface=DiagnosticMonitor
        required-com-specs:
          GetDTCOfEvent
          GetEventExtendedDataRecordEx
          GetEventFailed
          GetEventFreezeFrameDataEx
          GetEventStatus
          GetEventTested
          GetEventUdsStatus
          GetFaultDetectionCounter
          ResetEventDebounceStatus
          ResetEventStatus
          SetEventStatus
      DTC_RRALampCtlUnitPowerOL: required-interface=DiagnosticMonitor
        required-com-specs:
          GetDTCOfEvent
          GetEventExtendedDataRecordEx
          GetEventFailed
          GetEventFreezeFrameDataEx
          GetEventStatus
          GetEventTested
          GetEventUdsStatus
          GetFaultDetectionCounter
          ResetEventDebounceStatus
          ResetEventStatus
          SetEventStatus
      DTC_RRALampCtlUnitPowerSCB: required-interface=DiagnosticMonitor
        required-com-specs:
          GetDTCOfEvent
          GetEventExtendedDataRecordEx
          GetEventFailed
          GetEventFreezeFrameDataEx
          GetEventStatus
          GetEventTested
          GetEventUdsStatus
          GetFaultDetectionCounter
          ResetEventDebounceStatus
          ResetEventStatus
          SetEventStatus
      DTC_RRALampCtlUnitPowerSCG: required-interface=DiagnosticMonitor
        required-com-specs:
          GetDTCOfEvent
          GetEventExtendedDataRecordEx
          GetEventFailed
          GetEventFreezeFrameDataEx
          GetEventStatus
          GetEventTested
          GetEventUdsStatus
          GetFaultDetectionCounter
          ResetEventDebounceStatus
          ResetEventStatus
          SetEventStatus
      DTC_RRBLampCtlUnitPowerOC: required-interface=DiagnosticMonitor
        required-com-specs:
          GetDTCOfEvent
          GetEventExtendedDataRecordEx
          GetEventFailed
          GetEventFreezeFrameDataEx
          GetEventStatus
          GetEventTested
          GetEventUdsStatus
          GetFaultDetectionCounter
          ResetEventDebounceStatus
          ResetEventStatus
          SetEventStatus
      DTC_RRBLampCtlUnitPowerOL: required-interface=DiagnosticMonitor
        required-com-specs:
          GetDTCOfEvent
          GetEventExtendedDataRecordEx
          GetEventFailed
          GetEventFreezeFrameDataEx
          GetEventStatus
          GetEventTested
          GetEventUdsStatus
          GetFaultDetectionCounter
          ResetEventDebounceStatus
          ResetEventStatus
          SetEventStatus
      DTC_RRBLampCtlUnitPowerSCB: required-interface=DiagnosticMonitor
        required-com-specs:
          GetDTCOfEvent
          GetEventExtendedDataRecordEx
          GetEventFailed
          GetEventFreezeFrameDataEx
          GetEventStatus
          GetEventTested
          GetEventUdsStatus
          GetFaultDetectionCounter
          ResetEventDebounceStatus
          ResetEventStatus
          SetEventStatus
      DTC_RRBLampCtlUnitPowerSCG: required-interface=DiagnosticMonitor
        required-com-specs:
          GetDTCOfEvent
          GetEventExtendedDataRecordEx
          GetEventFailed
          GetEventFreezeFrameDataEx
          GetEventStatus
          GetEventTested
          GetEventUdsStatus
          GetFaultDetectionCounter
          ResetEventDebounceStatus
          ResetEventStatus
          SetEventStatus
      gPRM_au16OvrCurrDebTime: nonqueued-receiver-com-spec{data-element=gPRM_au16OvrCurrDebTime/Val, filter=data-filter-type=ALWAYS, init-value=25 x 500}, required-interface=gPRM_au16OvrCurrDebTime
      gPRM_au16OvrCurrThres: nonqueued-receiver-com-spec{data-element=gPRM_au16OvrCurrThres/Val, filter=data-filter-type=ALWAYS, init-value=[65535, 22000, 65535, 65535, 65535, 65535, 65535, 65535, 65535, 65535, 65535, 65535, 33000, 28000, 28000, 9500, 1700, 1700, 65535, 65535, 65535, 65535, 65535, 65535, 65535]}, required-interface=gPRM_au16OvrCurrThres
      gPRM_u8VehRLCM: nonqueued-receiver-com-spec{data-element=gPRM_u8VehRLCM/Val, filter=data-filter-type=ALWAYS, init-value=0}, required-interface=gPRM_u8VehRLCM
      gVRM_u16BatteryVolt_mv: nonqueued-receiver-com-spec{data-element=gVRM_u16BatteryVolt_mv/Val, filter=data-filter-type=ALWAYS, init-value=0}, required-interface=gVRM_u16BatteryVolt_mv
      IoHwAb_IoDiagDo: client-com-spec=Do_Get, required-interface=IoHwAb_IoDiagDo
      IoHwAb_IoDiagPwm: client-com-spec=Pwm_Get, required-interface=IoHwAb_IoDiagPwm
      IoHwAb_IoSigAdc: required-com-specs=[Adc_Get, AdcFac_Get, AdcVRMBatt_Get], required-interface=IoHwAb_IoSigAdc
      IoHwAb_IoSigDio: required-com-specs=[Di_Get, Do_Set], required-interface=IoHwAb_IoSigDio
      IoHwAb_IoSigPwm: required-com-specs=[Pwm_SetDuty, Pwm_SetPerd, Pwm_SetPerdAndDuty], required-interface=IoHwAb_IoSigPwm
      KL15PwrSply_bAMPPowerTrigUds: nonqueued-receiver-com-spec{data-element=KL15PwrSply_bAMPPowerTrigUds/Val, filter=data-filter-type=ALWAYS, init-value=0}, required-interface=KL15PwrSply_bAMPPowerTrigUds
      KL15PwrSply_bInverterPowerTrigUds: nonqueued-receiver-com-spec{data-element=KL15PwrSply_bInverterPowerTrigUds/Val, filter=data-filter-type=ALWAYS, init-value=0}, required-interface=KL15PwrSply_bInverterPowerTrigUds
      KL15PwrSply_bKL15T1PowerTrigUds: nonqueued-receiver-com-spec{data-element=KL15PwrSply_bKL15T1PowerTrigUds/Val, filter=data-filter-type=ALWAYS, init-value=0}, required-interface=KL15PwrSply_bKL15T1PowerTrigUds
      KL15PwrSply_bKL15T2PowerTrigUds: nonqueued-receiver-com-spec{data-element=KL15PwrSply_bKL15T2PowerTrigUds/Val, filter=data-filter-type=ALWAYS, init-value=0}, required-interface=KL15PwrSply_bKL15T2PowerTrigUds
      KL15PwrSply_bPCUPowerTrigUds: nonqueued-receiver-com-spec{data-element=KL15PwrSply_bPCUPowerTrigUds/Val, filter=data-filter-type=ALWAYS, init-value=0}, required-interface=KL15PwrSply_bPCUPowerTrigUds
      KL15PwrSply_bRear12VPowerTrigUds: nonqueued-receiver-com-spec{data-element=KL15PwrSply_bRear12VPowerTrigUds/Val, filter=data-filter-type=ALWAYS, init-value=0}, required-interface=KL15PwrSply_bRear12VPowerTrigUds
      KL15PwrSply_bRearBlowerPowerTrigUds: nonqueued-receiver-com-spec{data-element=KL15PwrSply_bRearBlowerPowerTrigUds/Val, filter=data-filter-type=ALWAYS, init-value=0}, required-interface=KL15PwrSply_bRearBlowerPowerTrigUds
      KL15PwrSply_bRearCtrlPanelPowerTrigUds: nonqueued-receiver-com-spec{data-element=KL15PwrSply_bRearCtrlPanelPowerTrigUds/Val, filter=data-filter-type=ALWAYS, init-value=0}, required-interface=KL15PwrSply_bRearCtrlPanelPowerTrigUds
      KL15PwrSply_bRearEOPPowerTrigUds: nonqueued-receiver-com-spec{data-element=KL15PwrSply_bRearEOPPowerTrigUds/Val, filter=data-filter-type=ALWAYS, init-value=0}, required-interface=KL15PwrSply_bRearEOPPowerTrigUds
      KL15PwrSply_bRearMotorPowerTrigUds: nonqueued-receiver-com-spec{data-element=KL15PwrSply_bRearMotorPowerTrigUds/Val, filter=data-filter-type=ALWAYS, init-value=0}, required-interface=KL15PwrSply_bRearMotorPowerTrigUds
      KL15PwrSply_bRearRadarPowerTrigUds: nonqueued-receiver-com-spec{data-element=KL15PwrSply_bRearRadarPowerTrigUds/Val, filter=data-filter-type=ALWAYS, init-value=0}, required-interface=KL15PwrSply_bRearRadarPowerTrigUds
      KL15PwrSply_bRLALampCtlUnitPowerTrigUds: nonqueued-receiver-com-spec{data-element=KL15PwrSply_bRLALampCtlUnitPowerTrigUds/Val, filter=data-filter-type=ALWAYS, init-value=0}, required-interface=KL15PwrSply_bRLALampCtlUnitPowerTrigUds
      KL15PwrSply_bRLBLampCtlUnitPowerTrigUds: nonqueued-receiver-com-spec{data-element=KL15PwrSply_bRLBLampCtlUnitPowerTrigUds/Val, filter=data-filter-type=ALWAYS, init-value=0}, required-interface=KL15PwrSply_bRLBLampCtlUnitPowerTrigUds
      KL15PwrSply_bRMPowerTrigUds: nonqueued-receiver-com-spec{data-element=KL15PwrSply_bRMPowerTrigUds/Val, filter=data-filter-type=ALWAYS, init-value=0}, required-interface=KL15PwrSply_bRMPowerTrigUds
      KL15PwrSply_bRRALampCtlUnitPowerTrigUds: nonqueued-receiver-com-spec{data-element=KL15PwrSply_bRRALampCtlUnitPowerTrigUds/Val, filter=data-filter-type=ALWAYS, init-value=0}, required-interface=KL15PwrSply_bRRALampCtlUnitPowerTrigUds
      KL15PwrSply_bRRBLampCtlUnitPowerTrigUds: nonqueued-receiver-com-spec{data-element=KL15PwrSply_bRRBLampCtlUnitPowerTrigUds/Val, filter=data-filter-type=ALWAYS, init-value=0}, required-interface=KL15PwrSply_bRRBLampCtlUnitPowerTrigUds
      KL15PwrSply_u8stAMPPowerUds: nonqueued-receiver-com-spec{data-element=KL15PwrSply_u8stAMPPowerUds/Val, filter=data-filter-type=ALWAYS, init-value=0}, required-interface=KL15PwrSply_u8stAMPPowerUds
      KL15PwrSply_u8stInverterPowerUds: nonqueued-receiver-com-spec{data-element=KL15PwrSply_u8stInverterPowerUds/Val, filter=data-filter-type=ALWAYS, init-value=0}, required-interface=KL15PwrSply_u8stInverterPowerUds
      KL15PwrSply_u8stKL15T1PowerUds: nonqueued-receiver-com-spec{data-element=KL15PwrSply_u8stKL15T1PowerUds/Val, filter=data-filter-type=ALWAYS, init-value=0}, required-interface=KL15PwrSply_u8stKL15T1PowerUds
      KL15PwrSply_u8stKL15T2PowerUds: nonqueued-receiver-com-spec{data-element=KL15PwrSply_u8stKL15T2PowerUds/Val, filter=data-filter-type=ALWAYS, init-value=0}, required-interface=KL15PwrSply_u8stKL15T2PowerUds
      KL15PwrSply_u8stPCUPowerUds: nonqueued-receiver-com-spec{data-element=KL15PwrSply_u8stPCUPowerUds/Val, filter=data-filter-type=ALWAYS, init-value=0}, required-interface=KL15PwrSply_u8stPCUPowerUds
      KL15PwrSply_u8stRear12VPowerUds: nonqueued-receiver-com-spec{data-element=KL15PwrSply_u8stRear12VPowerUds/Val, filter=data-filter-type=ALWAYS, init-value=0}, required-interface=KL15PwrSply_u8stRear12VPowerUds
      KL15PwrSply_u8stRearBlowerPowerUds: nonqueued-receiver-com-spec{data-element=KL15PwrSply_u8stRearBlowerPowerUds/Val, filter=data-filter-type=ALWAYS, init-value=0}, required-interface=KL15PwrSply_u8stRearBlowerPowerUds
      KL15PwrSply_u8stRearCtrlPanelPowerUds: nonqueued-receiver-com-spec{data-element=KL15PwrSply_u8stRearCtrlPanelPowerUds/Val, filter=data-filter-type=ALWAYS, init-value=0}, required-interface=KL15PwrSply_u8stRearCtrlPanelPowerUds
      KL15PwrSply_u8stRearEOPPowerUds: nonqueued-receiver-com-spec{data-element=KL15PwrSply_u8stRearEOPPowerUds/Val, filter=data-filter-type=ALWAYS, init-value=0}, required-interface=KL15PwrSply_u8stRearEOPPowerUds
      KL15PwrSply_u8stRearMotorPowerUds: nonqueued-receiver-com-spec{data-element=KL15PwrSply_u8stRearMotorPowerUds/Val, filter=data-filter-type=ALWAYS, init-value=0}, required-interface=KL15PwrSply_u8stRearMotorPowerUds
      KL15PwrSply_u8stRearRadarPowerUds: nonqueued-receiver-com-spec{data-element=KL15PwrSply_u8stRearRadarPowerUds/Val, filter=data-filter-type=ALWAYS, init-value=0}, required-interface=KL15PwrSply_u8stRearRadarPowerUds
      KL15PwrSply_u8stRLALampCtlUnitPowerUds: nonqueued-receiver-com-spec{data-element=KL15PwrSply_u8stRLALampCtlUnitPowerUds/Val, filter=data-filter-type=ALWAYS, init-value=0}, required-interface=KL15PwrSply_u8stRLALampCtlUnitPowerUds
      KL15PwrSply_u8stRLBLampCtlUnitPowerUds: nonqueued-receiver-com-spec{data-element=KL15PwrSply_u8stRLBLampCtlUnitPowerUds/Val, filter=data-filter-type=ALWAYS, init-value=0}, required-interface=KL15PwrSply_u8stRLBLampCtlUnitPowerUds
      KL15PwrSply_u8stRMPowerUds: nonqueued-receiver-com-spec{data-element=KL15PwrSply_u8stRMPowerUds/Val, filter=data-filter-type=ALWAYS, init-value=0}, required-interface=KL15PwrSply_u8stRMPowerUds
      KL15PwrSply_u8stRRALampCtlUnitPowerUds: nonqueued-receiver-com-spec{data-element=KL15PwrSply_u8stRRALampCtlUnitPowerUds/Val, filter=data-filter-type=ALWAYS, init-value=0}, required-interface=KL15PwrSply_u8stRRALampCtlUnitPowerUds
      KL15PwrSply_u8stRRBLampCtlUnitPowerUds: nonqueued-receiver-com-spec{data-element=KL15PwrSply_u8stRRBLampCtlUnitPowerUds/Val, filter=data-filter-type=ALWAYS, init-value=0}, required-interface=KL15PwrSply_u8stRRBLampCtlUnitPowerUds
      NMW_tGetAllCurrentComModeRTE: client-com-spec=NMW_tGetAllCurrentComModeRTE/Operation, required-interface=NMW_tGetAllCurrentComModeRTE
      NMW_tGetCurrentComModeRTE: client-com-spec=NMW_tGetCurrentComModeRTE/Operation, required-interface=NMW_tGetCurrentComModeRTE
      OilPmp_stReqIn: nonqueued-receiver-com-spec{data-element=OilPmp_stReqIn/Val, filter=data-filter-type=ALWAYS, init-value=0}, required-interface=OilPmp_stReqIn
      PwrSply_au8CoornReq: nonqueued-receiver-com-spec{data-element=PwrSply_au8CoornReq/Val, filter=data-filter-type=ALWAYS, init-value=29 x 0}, required-interface=PwrSply_au8CoornReq
      PwrSply_au8PwrSup: nonqueued-receiver-com-spec{data-element=PwrSply_au8PwrSup/Val, filter=data-filter-type=ALWAYS, init-value=29 x 0}, required-interface=PwrSply_au8PwrSup
      PwrSply_bCCULostComm: nonqueued-receiver-com-spec{data-element=PwrSply_bCCULostComm/Val, filter=data-filter-type=ALWAYS, init-value=0}, required-interface=PwrSply_bCCULostComm
      PwrSply_bNetSleepFlag: nonqueued-receiver-com-spec{data-element=PwrSply_bNetSleepFlag/Val, filter=data-filter-type=ALWAYS, init-value=0}, required-interface=PwrSply_bNetSleepFlag
      PwrSply_bPositionLightCtrlCmd{01..04}: nonqueued-receiver-com-spec{data-element=PwrSply_bPositionLightCtrlCmd{01..04}/Val, filter=data-filter-type=ALWAYS, init-value=0}, required-interface=PwrSply_bPositionLightCtrlCmd{01..04}
      PwrSply_bPositionLightTimingOFFEnableCfg: nonqueued-receiver-com-spec{data-element=PwrSply_bPositionLightTimingOFFEnableCfg/Val, filter=data-filter-type=ALWAYS, init-value=0}, required-interface=PwrSply_bPositionLightTimingOFFEnableCfg
      PwrSply_bVehSpdTkOvr: nonqueued-receiver-com-spec{data-element=PwrSply_bVehSpdTkOvr/Val, filter=data-filter-type=ALWAYS, init-value=0}, required-interface=PwrSply_bVehSpdTkOvr
      PwrSply_u8UMM_UsageModeSt: nonqueued-receiver-com-spec{data-element=PwrSply_u8UMM_UsageModeSt/Val, filter=data-filter-type=ALWAYS, init-value=0}, required-interface=PwrSply_u8UMM_UsageModeSt
      PwrSply_u8VehicleTypeCfg: nonqueued-receiver-com-spec{data-element=PwrSply_u8VehicleTypeCfg/Val, filter=data-filter-type=ALWAYS, init-value=0}, required-interface=PwrSply_u8VehicleTypeCfg
      PwrSply_u8VMM_OTAModeSt: nonqueued-receiver-com-spec{data-element=PwrSply_u8VMM_OTAModeSt/Val, filter=data-filter-type=ALWAYS, init-value=0}, required-interface=PwrSply_u8VMM_OTAModeSt
    behavior KL15PwrSply_DD_InternalBehavior: data-type-mapping=DTMS_FaultDiag
      timing event TMT_KL15PwrSply_DD_Runnable_10ms: start-on-event=KL15PwrSply_DD_Runnable_10ms, period=0.01
      init event KL15PwrSply_DD_Runnable_InitEvent: start-on-event=KL15PwrSply_DD_Runnable_Init
      port-api-options:
        enable-take-address=true, indirect-api=false, port=IoHwAb_IoSigDio
        enable-take-address=true, indirect-api=false, port=IoHwAb_IoSigPwm
      runnable KL15PwrSply_DD_Runnable_10ms
        data-read-access:
          51 x access:
            READ_BattU_bVoltEnbPinDiag_Val: accessed-variable=BattU_bVoltEnbPinDiag.Val
            READ_gPRM_au16OvrCurrDebTime_Val: accessed-variable=gPRM_au16OvrCurrDebTime.Val
            READ_gPRM_au16OvrCurrThres_Val: accessed-variable=gPRM_au16OvrCurrThres.Val
            READ_gPRM_u8VehRLCM_Val: accessed-variable=gPRM_u8VehRLCM.Val
            READ_gVRM_u16BatteryVolt_mv_Val: accessed-variable=gVRM_u16BatteryVolt_mv.Val
            READ_KL15PwrSply_bAMPPowerTrigUds_Val: accessed-variable=KL15PwrSply_bAMPPowerTrigUds.Val
            READ_KL15PwrSply_bInverterPowerTrigUds_Val: accessed-variable=KL15PwrSply_bInverterPowerTrigUds.Val
            READ_KL15PwrSply_bKL15T1PowerTrigUds_Val: accessed-variable=KL15PwrSply_bKL15T1PowerTrigUds.Val
            READ_KL15PwrSply_bKL15T2PowerTrigUds_Val: accessed-variable=KL15PwrSply_bKL15T2PowerTrigUds.Val
            READ_KL15PwrSply_bPCUPowerTrigUds_Val: accessed-variable=KL15PwrSply_bPCUPowerTrigUds.Val
            READ_KL15PwrSply_bRear12VPowerTrigUds_Val: accessed-variable=KL15PwrSply_bRear12VPowerTrigUds.Val
            READ_KL15PwrSply_bRearBlowerPowerTrigUds_Val: accessed-variable=KL15PwrSply_bRearBlowerPowerTrigUds.Val
            READ_KL15PwrSply_bRearCtrlPanelPowerTrigUds_Val: accessed-variable=KL15PwrSply_bRearCtrlPanelPowerTrigUds.Val
            READ_KL15PwrSply_bRearEOPPowerTrigUds_Val: accessed-variable=KL15PwrSply_bRearEOPPowerTrigUds.Val
            READ_KL15PwrSply_bRearMotorPowerTrigUds_Val: accessed-variable=KL15PwrSply_bRearMotorPowerTrigUds.Val
            READ_KL15PwrSply_bRearRadarPowerTrigUds_Val: accessed-variable=KL15PwrSply_bRearRadarPowerTrigUds.Val
            READ_KL15PwrSply_bRLALampCtlUnitPowerTrigUds_Val: accessed-variable=KL15PwrSply_bRLALampCtlUnitPowerTrigUds.Val
            READ_KL15PwrSply_bRLBLampCtlUnitPowerTrigUds_Val: accessed-variable=KL15PwrSply_bRLBLampCtlUnitPowerTrigUds.Val
            READ_KL15PwrSply_bRMPowerTrigUds_Val: accessed-variable=KL15PwrSply_bRMPowerTrigUds.Val
            READ_KL15PwrSply_bRRALampCtlUnitPowerTrigUds_Val: accessed-variable=KL15PwrSply_bRRALampCtlUnitPowerTrigUds.Val
            READ_KL15PwrSply_bRRBLampCtlUnitPowerTrigUds_Val: accessed-variable=KL15PwrSply_bRRBLampCtlUnitPowerTrigUds.Val
            READ_KL15PwrSply_u8stAMPPowerUds_Val: accessed-variable=KL15PwrSply_u8stAMPPowerUds.Val
            READ_KL15PwrSply_u8stInverterPowerUds_Val: accessed-variable=KL15PwrSply_u8stInverterPowerUds.Val
            READ_KL15PwrSply_u8stKL15T1PowerUds_Val: accessed-variable=KL15PwrSply_u8stKL15T1PowerUds.Val
            READ_KL15PwrSply_u8stKL15T2PowerUds_Val: accessed-variable=KL15PwrSply_u8stKL15T2PowerUds.Val
            READ_KL15PwrSply_u8stPCUPowerUds_Val: accessed-variable=KL15PwrSply_u8stPCUPowerUds.Val
            READ_KL15PwrSply_u8stRear12VPowerUds_Val: accessed-variable=KL15PwrSply_u8stRear12VPowerUds.Val
            READ_KL15PwrSply_u8stRearBlowerPowerUds_Val: accessed-variable=KL15PwrSply_u8stRearBlowerPowerUds.Val
            READ_KL15PwrSply_u8stRearCtrlPanelPowerUds_Val: accessed-variable=KL15PwrSply_u8stRearCtrlPanelPowerUds.Val
            READ_KL15PwrSply_u8stRearEOPPowerUds_Val: accessed-variable=KL15PwrSply_u8stRearEOPPowerUds.Val
            READ_KL15PwrSply_u8stRearMotorPowerUds_Val: accessed-variable=KL15PwrSply_u8stRearMotorPowerUds.Val
            READ_KL15PwrSply_u8stRearRadarPowerUds_Val: accessed-variable=KL15PwrSply_u8stRearRadarPowerUds.Val
            READ_KL15PwrSply_u8stRLALampCtlUnitPowerUds_Val: accessed-variable=KL15PwrSply_u8stRLALampCtlUnitPowerUds.Val
            READ_KL15PwrSply_u8stRLBLampCtlUnitPowerUds_Val: accessed-variable=KL15PwrSply_u8stRLBLampCtlUnitPowerUds.Val
            READ_KL15PwrSply_u8stRMPowerUds_Val: accessed-variable=KL15PwrSply_u8stRMPowerUds.Val
            READ_KL15PwrSply_u8stRRALampCtlUnitPowerUds_Val: accessed-variable=KL15PwrSply_u8stRRALampCtlUnitPowerUds.Val
            READ_KL15PwrSply_u8stRRBLampCtlUnitPowerUds_Val: accessed-variable=KL15PwrSply_u8stRRBLampCtlUnitPowerUds.Val
            READ_OilPmp_stReqIn_Val: accessed-variable=OilPmp_stReqIn.Val
            READ_PwrSply_au8CoornReq_Val: accessed-variable=PwrSply_au8CoornReq.Val
            READ_PwrSply_au8PwrSup_Val: accessed-variable=PwrSply_au8PwrSup.Val
            READ_PwrSply_bCCULostComm_Val: accessed-variable=PwrSply_bCCULostComm.Val
            READ_PwrSply_bNetSleepFlag_Val: accessed-variable=PwrSply_bNetSleepFlag.Val
            READ_PwrSply_bPositionLightCtrlCmd{01..04}_Val: accessed-variable=PwrSply_bPositionLightCtrlCmd{01..04}.Val
            READ_PwrSply_bPositionLightTimingOFFEnableCfg_Val: accessed-variable=PwrSply_bPositionLightTimingOFFEnableCfg.Val
            READ_PwrSply_bVehSpdTkOvr_Val: accessed-variable=PwrSply_bVehSpdTkOvr.Val
            READ_PwrSply_u8UMM_UsageModeSt_Val: accessed-variable=PwrSply_u8UMM_UsageModeSt.Val
            READ_PwrSply_u8VehicleTypeCfg_Val: accessed-variable=PwrSply_u8VehicleTypeCfg.Val
            READ_PwrSply_u8VMM_OTAModeSt_Val: accessed-variable=PwrSply_u8VMM_OTAModeSt.Val
        data-write-access:
          6 x access:
            WRITE_gKL15PwrSply_u32AllowSleep_Local_Val: accessed-variable=gKL15PwrSply_u32AllowSleep_Local.Val
            WRITE_gKL15PwrSply_u32AllowSleep_NW_Val: accessed-variable=gKL15PwrSply_u32AllowSleep_NW.Val
            WRITE_gKL15PwrSply_u8Wakeup_Val: accessed-variable=gKL15PwrSply_u8Wakeup.Val
            WRITE_PwrSply_abPwrSt_Val: accessed-variable=PwrSply_abPwrSt.Val
            WRITE_PwrSply_au16PwrCurr_Val: accessed-variable=PwrSply_au16PwrCurr.Val
            WRITE_PwrSply_au8PwrFaultSt_Val: accessed-variable=PwrSply_au8PwrFaultSt.Val
        66 x parameter access:
          PA_AMPPwrSply_OvrCurrThres_C: accessed-parameter=AMPPwrSply_OvrCurrThres_C
          PA_AMPPwrSply_StrtCurrIp_C: accessed-parameter=AMPPwrSply_StrtCurrIp_C
          PA_AMPPwrSply_TiKtp_C: accessed-parameter=AMPPwrSply_TiKtp_C
          PA_AMPPwrSply_TstCurr_C: accessed-parameter=AMPPwrSply_TstCurr_C
          PA_InverterPwrSply_OvrCurrThres_C: accessed-parameter=InverterPwrSply_OvrCurrThres_C
          PA_InverterPwrSply_StrtCurrIp_C: accessed-parameter=InverterPwrSply_StrtCurrIp_C
          PA_InverterPwrSply_TiKtp_C: accessed-parameter=InverterPwrSply_TiKtp_C
          PA_InverterPwrSply_TstCurr_C: accessed-parameter=InverterPwrSply_TstCurr_C
          PA_KL15T1PwrSply_OvrCurrThres_C: accessed-parameter=KL15T1PwrSply_OvrCurrThres_C
          PA_KL15T1PwrSply_StrtCurrIp_C: accessed-parameter=KL15T1PwrSply_StrtCurrIp_C
          PA_KL15T1PwrSply_TiKtp_C: accessed-parameter=KL15T1PwrSply_TiKtp_C
          PA_KL15T1PwrSply_TstCurr_C: accessed-parameter=KL15T1PwrSply_TstCurr_C
          PA_KL15T2PwrSply_OvrCurrThres_C: accessed-parameter=KL15T2PwrSply_OvrCurrThres_C
          PA_KL15T2PwrSply_StrtCurrIp_C: accessed-parameter=KL15T2PwrSply_StrtCurrIp_C
          PA_KL15T2PwrSply_TiKtp_C: accessed-parameter=KL15T2PwrSply_TiKtp_C
          PA_KL15T2PwrSply_TstCurr_C: accessed-parameter=KL15T2PwrSply_TstCurr_C
          PA_PCUPwrSply_OvrCurrThres_C: accessed-parameter=PCUPwrSply_OvrCurrThres_C
          PA_PCUPwrSply_StrtCurrIp_C: accessed-parameter=PCUPwrSply_StrtCurrIp_C
          PA_PCUPwrSply_TiKtp_C: accessed-parameter=PCUPwrSply_TiKtp_C
          PA_PCUPwrSply_TstCurr_C: accessed-parameter=PCUPwrSply_TstCurr_C
          PA_PwrSply_EnaOvrCurrThres_C: accessed-parameter=PwrSply_EnaOvrCurrThres_C
          PA_PwrSply_EnaTstCurr_C: accessed-parameter=PwrSply_EnaTstCurr_C
          PA_Rear12VPwrSply_OvrCurrThres_C: accessed-parameter=Rear12VPwrSply_OvrCurrThres_C
          PA_Rear12VPwrSply_StrtCurrIp_C: accessed-parameter=Rear12VPwrSply_StrtCurrIp_C
          PA_Rear12VPwrSply_TiKtp_C: accessed-parameter=Rear12VPwrSply_TiKtp_C
          PA_Rear12VPwrSply_TstCurr_C: accessed-parameter=Rear12VPwrSply_TstCurr_C
          PA_RearBlowerPwrSply_OvrCurrThres_C: accessed-parameter=RearBlowerPwrSply_OvrCurrThres_C
          PA_RearBlowerPwrSply_StrtCurrIp_C: accessed-parameter=RearBlowerPwrSply_StrtCurrIp_C
          PA_RearBlowerPwrSply_TiKtp_C: accessed-parameter=RearBlowerPwrSply_TiKtp_C
          PA_RearBlowerPwrSply_TstCurr_C: accessed-parameter=RearBlowerPwrSply_TstCurr_C
          PA_RearCtrlPwrSply_OvrCurrThres_C: accessed-parameter=RearCtrlPwrSply_OvrCurrThres_C
          PA_RearCtrlPwrSply_StrtCurrIp_C: accessed-parameter=RearCtrlPwrSply_StrtCurrIp_C
          PA_RearCtrlPwrSply_TiKtp_C: accessed-parameter=RearCtrlPwrSply_TiKtp_C
          PA_RearCtrlPwrSply_TstCurr_C: accessed-parameter=RearCtrlPwrSply_TstCurr_C
          PA_RearEOPPwrSply_OvrCurrThres_C: accessed-parameter=RearEOPPwrSply_OvrCurrThres_C
          PA_RearEOPPwrSply_StrtCurrIp_C: accessed-parameter=RearEOPPwrSply_StrtCurrIp_C
          PA_RearEOPPwrSply_TiKtp_C: accessed-parameter=RearEOPPwrSply_TiKtp_C
          PA_RearEOPPwrSply_TstCurr_C: accessed-parameter=RearEOPPwrSply_TstCurr_C
          PA_RearMotorPwrSply_OvrCurrThres_C: accessed-parameter=RearMotorPwrSply_OvrCurrThres_C
          PA_RearMotorPwrSply_StrtCurrIp_C: accessed-parameter=RearMotorPwrSply_StrtCurrIp_C
          PA_RearMotorPwrSply_TiKtp_C: accessed-parameter=RearMotorPwrSply_TiKtp_C
          PA_RearMotorPwrSply_TstCurr_C: accessed-parameter=RearMotorPwrSply_TstCurr_C
          PA_RearRadarPwrSply_OvrCurrThres_C: accessed-parameter=RearRadarPwrSply_OvrCurrThres_C
          PA_RearRadarPwrSply_StrtCurrIp_C: accessed-parameter=RearRadarPwrSply_StrtCurrIp_C
          PA_RearRadarPwrSply_TiKtp_C: accessed-parameter=RearRadarPwrSply_TiKtp_C
          PA_RearRadarPwrSply_TstCurr_C: accessed-parameter=RearRadarPwrSply_TstCurr_C
          PA_RLALampCtlUnitPwrSply_OvrCurrThres_C: accessed-parameter=RLALampCtlUnitPwrSply_OvrCurrThres_C
          PA_RLALampCtlUnitPwrSply_StrtCurrIp_C: accessed-parameter=RLALampCtlUnitPwrSply_StrtCurrIp_C
          PA_RLALampCtlUnitPwrSply_TiKtp_C: accessed-parameter=RLALampCtlUnitPwrSply_TiKtp_C
          PA_RLALampCtlUnitPwrSply_TstCurr_C: accessed-parameter=RLALampCtlUnitPwrSply_TstCurr_C
          PA_RLBLampCtlUnitPwrSply_OvrCurrThres_C: accessed-parameter=RLBLampCtlUnitPwrSply_OvrCurrThres_C
          PA_RLBLampCtlUnitPwrSply_StrtCurrIp_C: accessed-parameter=RLBLampCtlUnitPwrSply_StrtCurrIp_C
          PA_RLBLampCtlUnitPwrSply_TiKtp_C: accessed-parameter=RLBLampCtlUnitPwrSply_TiKtp_C
          PA_RLBLampCtlUnitPwrSply_TstCurr_C: accessed-parameter=RLBLampCtlUnitPwrSply_TstCurr_C
          PA_RMPwrSply_OvrCurrThres_C: accessed-parameter=RMPwrSply_OvrCurrThres_C
          PA_RMPwrSply_StrtCurrIp_C: accessed-parameter=RMPwrSply_StrtCurrIp_C
          PA_RMPwrSply_TiKtp_C: accessed-parameter=RMPwrSply_TiKtp_C
          PA_RMPwrSply_TstCurr_C: accessed-parameter=RMPwrSply_TstCurr_C
          PA_RRALampCtlUnitPwrSply_OvrCurrThres_C: accessed-parameter=RRALampCtlUnitPwrSply_OvrCurrThres_C
          PA_RRALampCtlUnitPwrSply_StrtCurrIp_C: accessed-parameter=RRALampCtlUnitPwrSply_StrtCurrIp_C
          PA_RRALampCtlUnitPwrSply_TiKtp_C: accessed-parameter=RRALampCtlUnitPwrSply_TiKtp_C
          PA_RRALampCtlUnitPwrSply_TstCurr_C: accessed-parameter=RRALampCtlUnitPwrSply_TstCurr_C
          PA_RRBLampCtlUnitPwrSply_OvrCurrThres_C: accessed-parameter=RRBLampCtlUnitPwrSply_OvrCurrThres_C
          PA_RRBLampCtlUnitPwrSply_StrtCurrIp_C: accessed-parameter=RRBLampCtlUnitPwrSply_StrtCurrIp_C
          PA_RRBLampCtlUnitPwrSply_TiKtp_C: accessed-parameter=RRBLampCtlUnitPwrSply_TiKtp_C
          PA_RRBLampCtlUnitPwrSply_TstCurr_C: accessed-parameter=RRBLampCtlUnitPwrSply_TstCurr_C
        215 x sync call:
          SC_DTC_AMPPowerOC_GetEventFailed: operation=DTC_AMPPowerOC.GetEventFailed, timeout=1E-06
          SC_DTC_AMPPowerOC_GetEventTested: operation=DTC_AMPPowerOC.GetEventTested, timeout=1E-06
          SC_DTC_AMPPowerOC_ResetEventDebounceStatus: operation=DTC_AMPPowerOC.ResetEventDebounceStatus, timeout=1E-06
          SC_DTC_AMPPowerOC_SetEventStatus: operation=DTC_AMPPowerOC.SetEventStatus, timeout=1E-06
          SC_DTC_AMPPowerOL_GetEventFailed: operation=DTC_AMPPowerOL.GetEventFailed, timeout=1E-06
          SC_DTC_AMPPowerOL_GetEventTested: operation=DTC_AMPPowerOL.GetEventTested, timeout=1E-06
          SC_DTC_AMPPowerOL_ResetEventDebounceStatus: operation=DTC_AMPPowerOL.ResetEventDebounceStatus, timeout=1E-06
          SC_DTC_AMPPowerOL_SetEventStatus: operation=DTC_AMPPowerOL.SetEventStatus, timeout=1E-06
          SC_DTC_AMPPowerSCB_GetEventFailed: operation=DTC_AMPPowerSCB.GetEventFailed, timeout=1E-06
          SC_DTC_AMPPowerSCB_GetEventTested: operation=DTC_AMPPowerSCB.GetEventTested, timeout=1E-06
          SC_DTC_AMPPowerSCB_ResetEventDebounceStatus: operation=DTC_AMPPowerSCB.ResetEventDebounceStatus, timeout=1E-06
          SC_DTC_AMPPowerSCB_SetEventStatus: operation=DTC_AMPPowerSCB.SetEventStatus, timeout=1E-06
          SC_DTC_AMPPowerSCG_GetEventFailed: operation=DTC_AMPPowerSCG.GetEventFailed, timeout=1E-06
          SC_DTC_AMPPowerSCG_GetEventTested: operation=DTC_AMPPowerSCG.GetEventTested, timeout=1E-06
          SC_DTC_AMPPowerSCG_ResetEventDebounceStatus: operation=DTC_AMPPowerSCG.ResetEventDebounceStatus, timeout=1E-06
          SC_DTC_AMPPowerSCG_SetEventStatus: operation=DTC_AMPPowerSCG.SetEventStatus, timeout=1E-06
          SC_DTC_InverterPowerOC_GetEventFailed: operation=DTC_InverterPowerOC.GetEventFailed, timeout=1E-06
          SC_DTC_InverterPowerOC_GetEventTested: operation=DTC_InverterPowerOC.GetEventTested, timeout=1E-06
          SC_DTC_InverterPowerOC_ResetEventDebounceStatus: operation=DTC_InverterPowerOC.ResetEventDebounceStatus, timeout=1E-06
          SC_DTC_InverterPowerOC_SetEventStatus: operation=DTC_InverterPowerOC.SetEventStatus, timeout=1E-06
          SC_DTC_InverterPowerOL_GetEventFailed: operation=DTC_InverterPowerOL.GetEventFailed, timeout=1E-06
          SC_DTC_InverterPowerOL_GetEventTested: operation=DTC_InverterPowerOL.GetEventTested, timeout=1E-06
          SC_DTC_InverterPowerOL_ResetEventDebounceStatus: operation=DTC_InverterPowerOL.ResetEventDebounceStatus, timeout=1E-06
          SC_DTC_InverterPowerOL_SetEventStatus: operation=DTC_InverterPowerOL.SetEventStatus, timeout=1E-06
          SC_DTC_InverterPowerSCB_GetEventFailed: operation=DTC_InverterPowerSCB.GetEventFailed, timeout=1E-06
          SC_DTC_InverterPowerSCB_GetEventTested: operation=DTC_InverterPowerSCB.GetEventTested, timeout=1E-06
          SC_DTC_InverterPowerSCB_ResetEventDebounceStatus: operation=DTC_InverterPowerSCB.ResetEventDebounceStatus, timeout=1E-06
          SC_DTC_InverterPowerSCB_SetEventStatus: operation=DTC_InverterPowerSCB.SetEventStatus, timeout=1E-06
          SC_DTC_InverterPowerSCG_GetEventFailed: operation=DTC_InverterPowerSCG.GetEventFailed, timeout=1E-06
          SC_DTC_InverterPowerSCG_GetEventTested: operation=DTC_InverterPowerSCG.GetEventTested, timeout=1E-06
          SC_DTC_InverterPowerSCG_ResetEventDebounceStatus: operation=DTC_InverterPowerSCG.ResetEventDebounceStatus, timeout=1E-06
          SC_DTC_InverterPowerSCG_SetEventStatus: operation=DTC_InverterPowerSCG.SetEventStatus, timeout=1E-06
          SC_DTC_PCUPowerOC_GetEventFailed: operation=DTC_PCUPowerOC.GetEventFailed, timeout=1E-06
          SC_DTC_PCUPowerOC_GetEventTested: operation=DTC_PCUPowerOC.GetEventTested, timeout=1E-06
          SC_DTC_PCUPowerOC_ResetEventDebounceStatus: operation=DTC_PCUPowerOC.ResetEventDebounceStatus, timeout=1E-06
          SC_DTC_PCUPowerOC_SetEventStatus: operation=DTC_PCUPowerOC.SetEventStatus, timeout=1E-06
          SC_DTC_PCUPowerOL_GetEventFailed: operation=DTC_PCUPowerOL.GetEventFailed, timeout=1E-06
          SC_DTC_PCUPowerOL_GetEventTested: operation=DTC_PCUPowerOL.GetEventTested, timeout=1E-06
          SC_DTC_PCUPowerOL_ResetEventDebounceStatus: operation=DTC_PCUPowerOL.ResetEventDebounceStatus, timeout=1E-06
          SC_DTC_PCUPowerOL_SetEventStatus: operation=DTC_PCUPowerOL.SetEventStatus, timeout=1E-06
          SC_DTC_PCUPowerSCB_GetEventFailed: operation=DTC_PCUPowerSCB.GetEventFailed, timeout=1E-06
          SC_DTC_PCUPowerSCB_GetEventTested: operation=DTC_PCUPowerSCB.GetEventTested, timeout=1E-06
          SC_DTC_PCUPowerSCB_ResetEventDebounceStatus: operation=DTC_PCUPowerSCB.ResetEventDebounceStatus, timeout=1E-06
          SC_DTC_PCUPowerSCB_SetEventStatus: operation=DTC_PCUPowerSCB.SetEventStatus, timeout=1E-06
          SC_DTC_PCUPowerSCG_GetEventFailed: operation=DTC_PCUPowerSCG.GetEventFailed, timeout=1E-06
          SC_DTC_PCUPowerSCG_GetEventTested: operation=DTC_PCUPowerSCG.GetEventTested, timeout=1E-06
          SC_DTC_PCUPowerSCG_ResetEventDebounceStatus: operation=DTC_PCUPowerSCG.ResetEventDebounceStatus, timeout=1E-06
          SC_DTC_PCUPowerSCG_SetEventStatus: operation=DTC_PCUPowerSCG.SetEventStatus, timeout=1E-06
          SC_DTC_Rear12VPowerOC_GetEventFailed: operation=DTC_Rear12VPowerOC.GetEventFailed, timeout=1E-06
          SC_DTC_Rear12VPowerOC_GetEventTested: operation=DTC_Rear12VPowerOC.GetEventTested, timeout=1E-06
          SC_DTC_Rear12VPowerOC_ResetEventDebounceStatus: operation=DTC_Rear12VPowerOC.ResetEventDebounceStatus, timeout=1E-06
          SC_DTC_Rear12VPowerOC_SetEventStatus: operation=DTC_Rear12VPowerOC.SetEventStatus, timeout=1E-06
          SC_DTC_Rear12VPowerOL_GetEventFailed: operation=DTC_Rear12VPowerOL.GetEventFailed, timeout=1E-06
          SC_DTC_Rear12VPowerOL_GetEventTested: operation=DTC_Rear12VPowerOL.GetEventTested, timeout=1E-06
          SC_DTC_Rear12VPowerOL_ResetEventDebounceStatus: operation=DTC_Rear12VPowerOL.ResetEventDebounceStatus, timeout=1E-06
          SC_DTC_Rear12VPowerOL_SetEventStatus: operation=DTC_Rear12VPowerOL.SetEventStatus, timeout=1E-06
          SC_DTC_Rear12VPowerSCB_GetEventFailed: operation=DTC_Rear12VPowerSCB.GetEventFailed, timeout=1E-06
          SC_DTC_Rear12VPowerSCB_GetEventTested: operation=DTC_Rear12VPowerSCB.GetEventTested, timeout=1E-06
          SC_DTC_Rear12VPowerSCB_ResetEventDebounceStatus: operation=DTC_Rear12VPowerSCB.ResetEventDebounceStatus, timeout=1E-06
          SC_DTC_Rear12VPowerSCB_SetEventStatus: operation=DTC_Rear12VPowerSCB.SetEventStatus, timeout=1E-06
          SC_DTC_Rear12VPowerSCG_GetEventFailed: operation=DTC_Rear12VPowerSCG.GetEventFailed, timeout=1E-06
          SC_DTC_Rear12VPowerSCG_GetEventTested: operation=DTC_Rear12VPowerSCG.GetEventTested, timeout=1E-06
          SC_DTC_Rear12VPowerSCG_ResetEventDebounceStatus: operation=DTC_Rear12VPowerSCG.ResetEventDebounceStatus, timeout=1E-06
          SC_DTC_Rear12VPowerSCG_SetEventStatus: operation=DTC_Rear12VPowerSCG.SetEventStatus, timeout=1E-06
          SC_DTC_RearBlowerPowerOC_GetEventFailed: operation=DTC_RearBlowerPowerOC.GetEventFailed, timeout=1E-06
          SC_DTC_RearBlowerPowerOC_GetEventTested: operation=DTC_RearBlowerPowerOC.GetEventTested, timeout=1E-06
          SC_DTC_RearBlowerPowerOC_ResetEventDebounceStatus: operation=DTC_RearBlowerPowerOC.ResetEventDebounceStatus, timeout=1E-06
          SC_DTC_RearBlowerPowerOC_SetEventStatus: operation=DTC_RearBlowerPowerOC.SetEventStatus, timeout=1E-06
          SC_DTC_RearBlowerPowerOL_GetEventFailed: operation=DTC_RearBlowerPowerOL.GetEventFailed, timeout=1E-06
          SC_DTC_RearBlowerPowerOL_GetEventTested: operation=DTC_RearBlowerPowerOL.GetEventTested, timeout=1E-06
          SC_DTC_RearBlowerPowerOL_ResetEventDebounceStatus: operation=DTC_RearBlowerPowerOL.ResetEventDebounceStatus, timeout=1E-06
          SC_DTC_RearBlowerPowerOL_SetEventStatus: operation=DTC_RearBlowerPowerOL.SetEventStatus, timeout=1E-06
          SC_DTC_RearBlowerPowerSCB_GetEventFailed: operation=DTC_RearBlowerPowerSCB.GetEventFailed, timeout=1E-06
          SC_DTC_RearBlowerPowerSCB_GetEventTested: operation=DTC_RearBlowerPowerSCB.GetEventTested, timeout=1E-06
          SC_DTC_RearBlowerPowerSCB_ResetEventDebounceStatus: operation=DTC_RearBlowerPowerSCB.ResetEventDebounceStatus, timeout=1E-06
          SC_DTC_RearBlowerPowerSCB_SetEventStatus: operation=DTC_RearBlowerPowerSCB.SetEventStatus, timeout=1E-06
          SC_DTC_RearBlowerPowerSCG_GetEventFailed: operation=DTC_RearBlowerPowerSCG.GetEventFailed, timeout=1E-06
          SC_DTC_RearBlowerPowerSCG_GetEventTested: operation=DTC_RearBlowerPowerSCG.GetEventTested, timeout=1E-06
          SC_DTC_RearBlowerPowerSCG_ResetEventDebounceStatus: operation=DTC_RearBlowerPowerSCG.ResetEventDebounceStatus, timeout=1E-06
          SC_DTC_RearBlowerPowerSCG_SetEventStatus: operation=DTC_RearBlowerPowerSCG.SetEventStatus, timeout=1E-06
          SC_DTC_RearEOPPowerOC_GetEventFailed: operation=DTC_RearEOPPowerOC.GetEventFailed, timeout=1E-06
          SC_DTC_RearEOPPowerOC_GetEventTested: operation=DTC_RearEOPPowerOC.GetEventTested, timeout=1E-06
          SC_DTC_RearEOPPowerOC_ResetEventDebounceStatus: operation=DTC_RearEOPPowerOC.ResetEventDebounceStatus, timeout=1E-06
          SC_DTC_RearEOPPowerOC_SetEventStatus: operation=DTC_RearEOPPowerOC.SetEventStatus, timeout=1E-06
          SC_DTC_RearEOPPowerOL_GetEventFailed: operation=DTC_RearEOPPowerOL.GetEventFailed, timeout=1E-06
          SC_DTC_RearEOPPowerOL_GetEventTested: operation=DTC_RearEOPPowerOL.GetEventTested, timeout=1E-06
          SC_DTC_RearEOPPowerOL_ResetEventDebounceStatus: operation=DTC_RearEOPPowerOL.ResetEventDebounceStatus, timeout=1E-06
          SC_DTC_RearEOPPowerOL_SetEventStatus: operation=DTC_RearEOPPowerOL.SetEventStatus, timeout=1E-06
          SC_DTC_RearEOPPowerSCB_GetEventFailed: operation=DTC_RearEOPPowerSCB.GetEventFailed, timeout=1E-06
          SC_DTC_RearEOPPowerSCB_GetEventTested: operation=DTC_RearEOPPowerSCB.GetEventTested, timeout=1E-06
          SC_DTC_RearEOPPowerSCB_ResetEventDebounceStatus: operation=DTC_RearEOPPowerSCB.ResetEventDebounceStatus, timeout=1E-06
          SC_DTC_RearEOPPowerSCB_SetEventStatus: operation=DTC_RearEOPPowerSCB.SetEventStatus, timeout=1E-06
          SC_DTC_RearEOPPowerSCG_GetEventFailed: operation=DTC_RearEOPPowerSCG.GetEventFailed, timeout=1E-06
          SC_DTC_RearEOPPowerSCG_GetEventTested: operation=DTC_RearEOPPowerSCG.GetEventTested, timeout=1E-06
          SC_DTC_RearEOPPowerSCG_ResetEventDebounceStatus: operation=DTC_RearEOPPowerSCG.ResetEventDebounceStatus, timeout=1E-06
          SC_DTC_RearEOPPowerSCG_SetEventStatus: operation=DTC_RearEOPPowerSCG.SetEventStatus, timeout=1E-06
          SC_DTC_RearMotorPowerOC_GetEventFailed: operation=DTC_RearMotorPowerOC.GetEventFailed, timeout=1E-06
          SC_DTC_RearMotorPowerOC_GetEventTested: operation=DTC_RearMotorPowerOC.GetEventTested, timeout=1E-06
          SC_DTC_RearMotorPowerOC_ResetEventDebounceStatus: operation=DTC_RearMotorPowerOC.ResetEventDebounceStatus, timeout=1E-06
          SC_DTC_RearMotorPowerOC_SetEventStatus: operation=DTC_RearMotorPowerOC.SetEventStatus, timeout=1E-06
          SC_DTC_RearMotorPowerOL_GetEventFailed: operation=DTC_RearMotorPowerOL.GetEventFailed, timeout=1E-06
          SC_DTC_RearMotorPowerOL_GetEventTested: operation=DTC_RearMotorPowerOL.GetEventTested, timeout=1E-06
          SC_DTC_RearMotorPowerOL_ResetEventDebounceStatus: operation=DTC_RearMotorPowerOL.ResetEventDebounceStatus, timeout=1E-06
          SC_DTC_RearMotorPowerOL_SetEventStatus: operation=DTC_RearMotorPowerOL.SetEventStatus, timeout=1E-06
          SC_DTC_RearMotorPowerSCB_GetEventFailed: operation=DTC_RearMotorPowerSCB.GetEventFailed, timeout=1E-06
          SC_DTC_RearMotorPowerSCB_GetEventTested: operation=DTC_RearMotorPowerSCB.GetEventTested, timeout=1E-06
          SC_DTC_RearMotorPowerSCB_ResetEventDebounceStatus: operation=DTC_RearMotorPowerSCB.ResetEventDebounceStatus, timeout=1E-06
          SC_DTC_RearMotorPowerSCB_SetEventStatus: operation=DTC_RearMotorPowerSCB.SetEventStatus, timeout=1E-06
          SC_DTC_RearMotorPowerSCG_GetEventFailed: operation=DTC_RearMotorPowerSCG.GetEventFailed, timeout=1E-06
          SC_DTC_RearMotorPowerSCG_GetEventTested: operation=DTC_RearMotorPowerSCG.GetEventTested, timeout=1E-06
          SC_DTC_RearMotorPowerSCG_ResetEventDebounceStatus: operation=DTC_RearMotorPowerSCG.ResetEventDebounceStatus, timeout=1E-06
          SC_DTC_RearMotorPowerSCG_SetEventStatus: operation=DTC_RearMotorPowerSCG.SetEventStatus, timeout=1E-06
          SC_DTC_RearRadarPowerOC_GetEventFailed: operation=DTC_RearRadarPowerOC.GetEventFailed, timeout=1E-06
          SC_DTC_RearRadarPowerOC_GetEventTested: operation=DTC_RearRadarPowerOC.GetEventTested, timeout=1E-06
          SC_DTC_RearRadarPowerOC_ResetEventDebounceStatus: operation=DTC_RearRadarPowerOC.ResetEventDebounceStatus, timeout=1E-06
          SC_DTC_RearRadarPowerOC_SetEventStatus: operation=DTC_RearRadarPowerOC.SetEventStatus, timeout=1E-06
          SC_DTC_RearRadarPowerOL_GetEventFailed: operation=DTC_RearRadarPowerOL.GetEventFailed, timeout=1E-06
          SC_DTC_RearRadarPowerOL_GetEventTested: operation=DTC_RearRadarPowerOL.GetEventTested, timeout=1E-06
          SC_DTC_RearRadarPowerOL_ResetEventDebounceStatus: operation=DTC_RearRadarPowerOL.ResetEventDebounceStatus, timeout=1E-06
          SC_DTC_RearRadarPowerOL_SetEventStatus: operation=DTC_RearRadarPowerOL.SetEventStatus, timeout=1E-06
          SC_DTC_RearRadarPowerSCB_GetEventFailed: operation=DTC_RearRadarPowerSCB.GetEventFailed, timeout=1E-06
          SC_DTC_RearRadarPowerSCB_GetEventTested: operation=DTC_RearRadarPowerSCB.GetEventTested, timeout=1E-06
          SC_DTC_RearRadarPowerSCB_ResetEventDebounceStatus: operation=DTC_RearRadarPowerSCB.ResetEventDebounceStatus, timeout=1E-06
          SC_DTC_RearRadarPowerSCB_SetEventStatus: operation=DTC_RearRadarPowerSCB.SetEventStatus, timeout=1E-06
          SC_DTC_RearRadarPowerSCG_GetEventFailed: operation=DTC_RearRadarPowerSCG.GetEventFailed, timeout=1E-06
          SC_DTC_RearRadarPowerSCG_GetEventTested: operation=DTC_RearRadarPowerSCG.GetEventTested, timeout=1E-06
          SC_DTC_RearRadarPowerSCG_ResetEventDebounceStatus: operation=DTC_RearRadarPowerSCG.ResetEventDebounceStatus, timeout=1E-06
          SC_DTC_RearRadarPowerSCG_SetEventStatus: operation=DTC_RearRadarPowerSCG.SetEventStatus, timeout=1E-06
          SC_DTC_RLALampCtlUnitPowerOC_GetEventFailed: operation=DTC_RLALampCtlUnitPowerOC.GetEventFailed, timeout=1E-06
          SC_DTC_RLALampCtlUnitPowerOC_GetEventTested: operation=DTC_RLALampCtlUnitPowerOC.GetEventTested, timeout=1E-06
          SC_DTC_RLALampCtlUnitPowerOC_ResetEventDebounceStatus: operation=DTC_RLALampCtlUnitPowerOC.ResetEventDebounceStatus, timeout=1E-06
          SC_DTC_RLALampCtlUnitPowerOC_SetEventStatus: operation=DTC_RLALampCtlUnitPowerOC.SetEventStatus, timeout=1E-06
          SC_DTC_RLALampCtlUnitPowerOL_GetEventFailed: operation=DTC_RLALampCtlUnitPowerOL.GetEventFailed, timeout=1E-06
          SC_DTC_RLALampCtlUnitPowerOL_GetEventTested: operation=DTC_RLALampCtlUnitPowerOL.GetEventTested, timeout=1E-06
          SC_DTC_RLALampCtlUnitPowerOL_ResetEventDebounceStatus: operation=DTC_RLALampCtlUnitPowerOL.ResetEventDebounceStatus, timeout=1E-06
          SC_DTC_RLALampCtlUnitPowerOL_SetEventStatus: operation=DTC_RLALampCtlUnitPowerOL.SetEventStatus, timeout=1E-06
          SC_DTC_RLALampCtlUnitPowerSCB_GetEventFailed: operation=DTC_RLALampCtlUnitPowerSCB.GetEventFailed, timeout=1E-06
          SC_DTC_RLALampCtlUnitPowerSCB_GetEventTested: operation=DTC_RLALampCtlUnitPowerSCB.GetEventTested, timeout=1E-06
          SC_DTC_RLALampCtlUnitPowerSCB_ResetEventDebounceStatus: operation=DTC_RLALampCtlUnitPowerSCB.ResetEventDebounceStatus, timeout=1E-06
          SC_DTC_RLALampCtlUnitPowerSCB_SetEventStatus: operation=DTC_RLALampCtlUnitPowerSCB.SetEventStatus, timeout=1E-06
          SC_DTC_RLALampCtlUnitPowerSCG_GetEventFailed: operation=DTC_RLALampCtlUnitPowerSCG.GetEventFailed, timeout=1E-06
          SC_DTC_RLALampCtlUnitPowerSCG_GetEventTested: operation=DTC_RLALampCtlUnitPowerSCG.GetEventTested, timeout=1E-06
          SC_DTC_RLALampCtlUnitPowerSCG_ResetEventDebounceStatus: operation=DTC_RLALampCtlUnitPowerSCG.ResetEventDebounceStatus, timeout=1E-06
          SC_DTC_RLALampCtlUnitPowerSCG_SetEventStatus: operation=DTC_RLALampCtlUnitPowerSCG.SetEventStatus, timeout=1E-06
          SC_DTC_RLBLampCtlUnitPowerOC_GetEventFailed: operation=DTC_RLBLampCtlUnitPowerOC.GetEventFailed, timeout=1E-06
          SC_DTC_RLBLampCtlUnitPowerOC_GetEventTested: operation=DTC_RLBLampCtlUnitPowerOC.GetEventTested, timeout=1E-06
          SC_DTC_RLBLampCtlUnitPowerOC_ResetEventDebounceStatus: operation=DTC_RLBLampCtlUnitPowerOC.ResetEventDebounceStatus, timeout=1E-06
          SC_DTC_RLBLampCtlUnitPowerOC_SetEventStatus: operation=DTC_RLBLampCtlUnitPowerOC.SetEventStatus, timeout=1E-06
          SC_DTC_RLBLampCtlUnitPowerOL_GetEventFailed: operation=DTC_RLBLampCtlUnitPowerOL.GetEventFailed, timeout=1E-06
          SC_DTC_RLBLampCtlUnitPowerOL_GetEventTested: operation=DTC_RLBLampCtlUnitPowerOL.GetEventTested, timeout=1E-06
          SC_DTC_RLBLampCtlUnitPowerOL_ResetEventDebounceStatus: operation=DTC_RLBLampCtlUnitPowerOL.ResetEventDebounceStatus, timeout=1E-06
          SC_DTC_RLBLampCtlUnitPowerOL_SetEventStatus: operation=DTC_RLBLampCtlUnitPowerOL.SetEventStatus, timeout=1E-06
          SC_DTC_RLBLampCtlUnitPowerSCB_GetEventFailed: operation=DTC_RLBLampCtlUnitPowerSCB.GetEventFailed, timeout=1E-06
          SC_DTC_RLBLampCtlUnitPowerSCB_GetEventTested: operation=DTC_RLBLampCtlUnitPowerSCB.GetEventTested, timeout=1E-06
          SC_DTC_RLBLampCtlUnitPowerSCB_ResetEventDebounceStatus: operation=DTC_RLBLampCtlUnitPowerSCB.ResetEventDebounceStatus, timeout=1E-06
          SC_DTC_RLBLampCtlUnitPowerSCB_SetEventStatus: operation=DTC_RLBLampCtlUnitPowerSCB.SetEventStatus, timeout=1E-06
          SC_DTC_RLBLampCtlUnitPowerSCG_GetEventFailed: operation=DTC_RLBLampCtlUnitPowerSCG.GetEventFailed, timeout=1E-06
          SC_DTC_RLBLampCtlUnitPowerSCG_GetEventTested: operation=DTC_RLBLampCtlUnitPowerSCG.GetEventTested, timeout=1E-06
          SC_DTC_RLBLampCtlUnitPowerSCG_ResetEventDebounceStatus: operation=DTC_RLBLampCtlUnitPowerSCG.ResetEventDebounceStatus, timeout=1E-06
          SC_DTC_RLBLampCtlUnitPowerSCG_SetEventStatus: operation=DTC_RLBLampCtlUnitPowerSCG.SetEventStatus, timeout=1E-06
          SC_DTC_RMPowerOC_GetEventFailed: operation=DTC_RMPowerOC.GetEventFailed, timeout=1E-06
          SC_DTC_RMPowerOC_GetEventTested: operation=DTC_RMPowerOC.GetEventTested, timeout=1E-06
          SC_DTC_RMPowerOC_ResetEventDebounceStatus: operation=DTC_RMPowerOC.ResetEventDebounceStatus, timeout=1E-06
          SC_DTC_RMPowerOC_SetEventStatus: operation=DTC_RMPowerOC.SetEventStatus, timeout=1E-06
          SC_DTC_RMPowerOL_GetEventFailed: operation=DTC_RMPowerOL.GetEventFailed, timeout=1E-06
          SC_DTC_RMPowerOL_GetEventTested: operation=DTC_RMPowerOL.GetEventTested, timeout=1E-06
          SC_DTC_RMPowerOL_ResetEventDebounceStatus: operation=DTC_RMPowerOL.ResetEventDebounceStatus, timeout=1E-06
          SC_DTC_RMPowerOL_SetEventStatus: operation=DTC_RMPowerOL.SetEventStatus, timeout=1E-06
          SC_DTC_RMPowerSCB_GetEventFailed: operation=DTC_RMPowerSCB.GetEventFailed, timeout=1E-06
          SC_DTC_RMPowerSCB_GetEventTested: operation=DTC_RMPowerSCB.GetEventTested, timeout=1E-06
          SC_DTC_RMPowerSCB_ResetEventDebounceStatus: operation=DTC_RMPowerSCB.ResetEventDebounceStatus, timeout=1E-06
          SC_DTC_RMPowerSCB_SetEventStatus: operation=DTC_RMPowerSCB.SetEventStatus, timeout=1E-06
          SC_DTC_RMPowerSCG_GetEventFailed: operation=DTC_RMPowerSCG.GetEventFailed, timeout=1E-06
          SC_DTC_RMPowerSCG_GetEventTested: operation=DTC_RMPowerSCG.GetEventTested, timeout=1E-06
          SC_DTC_RMPowerSCG_ResetEventDebounceStatus: operation=DTC_RMPowerSCG.ResetEventDebounceStatus, timeout=1E-06
          SC_DTC_RMPowerSCG_SetEventStatus: operation=DTC_RMPowerSCG.SetEventStatus, timeout=1E-06
          SC_DTC_RRALampCtlUnitPowerOC_GetEventFailed: operation=DTC_RRALampCtlUnitPowerOC.GetEventFailed, timeout=1E-06
          SC_DTC_RRALampCtlUnitPowerOC_GetEventTested: operation=DTC_RRALampCtlUnitPowerOC.GetEventTested, timeout=1E-06
          SC_DTC_RRALampCtlUnitPowerOC_ResetEventDebounceStatus: operation=DTC_RRALampCtlUnitPowerOC.ResetEventDebounceStatus, timeout=1E-06
          SC_DTC_RRALampCtlUnitPowerOC_SetEventStatus: operation=DTC_RRALampCtlUnitPowerOC.SetEventStatus, timeout=1E-06
          SC_DTC_RRALampCtlUnitPowerOL_GetEventFailed: operation=DTC_RRALampCtlUnitPowerOL.GetEventFailed, timeout=1E-06
          SC_DTC_RRALampCtlUnitPowerOL_GetEventTested: operation=DTC_RRALampCtlUnitPowerOL.GetEventTested, timeout=1E-06
          SC_DTC_RRALampCtlUnitPowerOL_ResetEventDebounceStatus: operation=DTC_RRALampCtlUnitPowerOL.ResetEventDebounceStatus, timeout=1E-06
          SC_DTC_RRALampCtlUnitPowerOL_SetEventStatus: operation=DTC_RRALampCtlUnitPowerOL.SetEventStatus, timeout=1E-06
          SC_DTC_RRALampCtlUnitPowerSCB_GetEventFailed: operation=DTC_RRALampCtlUnitPowerSCB.GetEventFailed, timeout=1E-06
          SC_DTC_RRALampCtlUnitPowerSCB_GetEventTested: operation=DTC_RRALampCtlUnitPowerSCB.GetEventTested, timeout=1E-06
          SC_DTC_RRALampCtlUnitPowerSCB_ResetEventDebounceStatus: operation=DTC_RRALampCtlUnitPowerSCB.ResetEventDebounceStatus, timeout=1E-06
          SC_DTC_RRALampCtlUnitPowerSCB_SetEventStatus: operation=DTC_RRALampCtlUnitPowerSCB.SetEventStatus, timeout=1E-06
          SC_DTC_RRALampCtlUnitPowerSCG_GetEventFailed: operation=DTC_RRALampCtlUnitPowerSCG.GetEventFailed, timeout=1E-06
          SC_DTC_RRALampCtlUnitPowerSCG_GetEventTested: operation=DTC_RRALampCtlUnitPowerSCG.GetEventTested, timeout=1E-06
          SC_DTC_RRALampCtlUnitPowerSCG_ResetEventDebounceStatus: operation=DTC_RRALampCtlUnitPowerSCG.ResetEventDebounceStatus, timeout=1E-06
          SC_DTC_RRALampCtlUnitPowerSCG_SetEventStatus: operation=DTC_RRALampCtlUnitPowerSCG.SetEventStatus, timeout=1E-06
          SC_DTC_RRBLampCtlUnitPowerOC_GetEventFailed: operation=DTC_RRBLampCtlUnitPowerOC.GetEventFailed, timeout=1E-06
          SC_DTC_RRBLampCtlUnitPowerOC_GetEventTested: operation=DTC_RRBLampCtlUnitPowerOC.GetEventTested, timeout=1E-06
          SC_DTC_RRBLampCtlUnitPowerOC_ResetEventDebounceStatus: operation=DTC_RRBLampCtlUnitPowerOC.ResetEventDebounceStatus, timeout=1E-06
          SC_DTC_RRBLampCtlUnitPowerOC_SetEventStatus: operation=DTC_RRBLampCtlUnitPowerOC.SetEventStatus, timeout=1E-06
          SC_DTC_RRBLampCtlUnitPowerOL_GetEventFailed: operation=DTC_RRBLampCtlUnitPowerOL.GetEventFailed, timeout=1E-06
          SC_DTC_RRBLampCtlUnitPowerOL_GetEventTested: operation=DTC_RRBLampCtlUnitPowerOL.GetEventTested, timeout=1E-06
          SC_DTC_RRBLampCtlUnitPowerOL_ResetEventDebounceStatus: operation=DTC_RRBLampCtlUnitPowerOL.ResetEventDebounceStatus, timeout=1E-06
          SC_DTC_RRBLampCtlUnitPowerOL_SetEventStatus: operation=DTC_RRBLampCtlUnitPowerOL.SetEventStatus, timeout=1E-06
          SC_DTC_RRBLampCtlUnitPowerSCB_GetEventFailed: operation=DTC_RRBLampCtlUnitPowerSCB.GetEventFailed, timeout=1E-06
          SC_DTC_RRBLampCtlUnitPowerSCB_GetEventTested: operation=DTC_RRBLampCtlUnitPowerSCB.GetEventTested, timeout=1E-06
          SC_DTC_RRBLampCtlUnitPowerSCB_ResetEventDebounceStatus: operation=DTC_RRBLampCtlUnitPowerSCB.ResetEventDebounceStatus, timeout=1E-06
          SC_DTC_RRBLampCtlUnitPowerSCB_SetEventStatus: operation=DTC_RRBLampCtlUnitPowerSCB.SetEventStatus, timeout=1E-06
          SC_DTC_RRBLampCtlUnitPowerSCG_GetEventFailed: operation=DTC_RRBLampCtlUnitPowerSCG.GetEventFailed, timeout=1E-06
          SC_DTC_RRBLampCtlUnitPowerSCG_GetEventTested: operation=DTC_RRBLampCtlUnitPowerSCG.GetEventTested, timeout=1E-06
          SC_DTC_RRBLampCtlUnitPowerSCG_ResetEventDebounceStatus: operation=DTC_RRBLampCtlUnitPowerSCG.ResetEventDebounceStatus, timeout=1E-06
          SC_DTC_RRBLampCtlUnitPowerSCG_SetEventStatus: operation=DTC_RRBLampCtlUnitPowerSCG.SetEventStatus, timeout=1E-06
          SC_IoHwAb_IoDiagDo_Do_Get: operation=IoHwAb_IoDiagDo.Do_Get, timeout=0
          SC_IoHwAb_IoDiagPwm_Pwm_Get: operation=IoHwAb_IoDiagPwm.Pwm_Get, timeout=0
          SC_IoHwAb_IoSigAdc_Adc_Get: operation=IoHwAb_IoSigAdc.Adc_Get, timeout=0
          SC_IoHwAb_IoSigDio_Do_Set: operation=IoHwAb_IoSigDio.Do_Set, timeout=0
          SC_IoHwAb_IoSigPwm_Pwm_SetDuty: operation=IoHwAb_IoSigPwm.Pwm_SetDuty, timeout=0
          SC_NMW_tGetAllCurrentComModeRTE_Operation: operation=NMW_tGetAllCurrentComModeRTE.Operation, timeout=0
          SC_NMW_tGetCurrentComModeRTE_Operation: operation=NMW_tGetCurrentComModeRTE.Operation, timeout=0
      runnable KL15PwrSply_DD_Runnable_Init
        data-write-access:
          6 x access:
            WRITE_gKL15PwrSply_u32AllowSleep_Local_Val: accessed-variable=gKL15PwrSply_u32AllowSleep_Local.Val
            WRITE_gKL15PwrSply_u32AllowSleep_NW_Val: accessed-variable=gKL15PwrSply_u32AllowSleep_NW.Val
            WRITE_gKL15PwrSply_u8Wakeup_Val: accessed-variable=gKL15PwrSply_u8Wakeup.Val
            WRITE_PwrSply_abPwrSt_Val: accessed-variable=PwrSply_abPwrSt.Val
            WRITE_PwrSply_au16PwrCurr_Val: accessed-variable=PwrSply_au16PwrCurr.Val
            WRITE_PwrSply_au8PwrFaultSt_Val: accessed-variable=PwrSply_au8PwrFaultSt.Val
        66 x parameter access:
          PA_AMPPwrSply_OvrCurrThres_C: accessed-parameter=AMPPwrSply_OvrCurrThres_C
          PA_AMPPwrSply_StrtCurrIp_C: accessed-parameter=AMPPwrSply_StrtCurrIp_C
          PA_AMPPwrSply_TiKtp_C: accessed-parameter=AMPPwrSply_TiKtp_C
          PA_AMPPwrSply_TstCurr_C: accessed-parameter=AMPPwrSply_TstCurr_C
          PA_InverterPwrSply_OvrCurrThres_C: accessed-parameter=InverterPwrSply_OvrCurrThres_C
          PA_InverterPwrSply_StrtCurrIp_C: accessed-parameter=InverterPwrSply_StrtCurrIp_C
          PA_InverterPwrSply_TiKtp_C: accessed-parameter=InverterPwrSply_TiKtp_C
          PA_InverterPwrSply_TstCurr_C: accessed-parameter=InverterPwrSply_TstCurr_C
          PA_KL15T1PwrSply_OvrCurrThres_C: accessed-parameter=KL15T1PwrSply_OvrCurrThres_C
          PA_KL15T1PwrSply_StrtCurrIp_C: accessed-parameter=KL15T1PwrSply_StrtCurrIp_C
          PA_KL15T1PwrSply_TiKtp_C: accessed-parameter=KL15T1PwrSply_TiKtp_C
          PA_KL15T1PwrSply_TstCurr_C: accessed-parameter=KL15T1PwrSply_TstCurr_C
          PA_KL15T2PwrSply_OvrCurrThres_C: accessed-parameter=KL15T2PwrSply_OvrCurrThres_C
          PA_KL15T2PwrSply_StrtCurrIp_C: accessed-parameter=KL15T2PwrSply_StrtCurrIp_C
          PA_KL15T2PwrSply_TiKtp_C: accessed-parameter=KL15T2PwrSply_TiKtp_C
          PA_KL15T2PwrSply_TstCurr_C: accessed-parameter=KL15T2PwrSply_TstCurr_C
          PA_PCUPwrSply_OvrCurrThres_C: accessed-parameter=PCUPwrSply_OvrCurrThres_C
          PA_PCUPwrSply_StrtCurrIp_C: accessed-parameter=PCUPwrSply_StrtCurrIp_C
          PA_PCUPwrSply_TiKtp_C: accessed-parameter=PCUPwrSply_TiKtp_C
          PA_PCUPwrSply_TstCurr_C: accessed-parameter=PCUPwrSply_TstCurr_C
          PA_PwrSply_EnaOvrCurrThres_C: accessed-parameter=PwrSply_EnaOvrCurrThres_C
          PA_PwrSply_EnaTstCurr_C: accessed-parameter=PwrSply_EnaTstCurr_C
          PA_Rear12VPwrSply_OvrCurrThres_C: accessed-parameter=Rear12VPwrSply_OvrCurrThres_C
          PA_Rear12VPwrSply_StrtCurrIp_C: accessed-parameter=Rear12VPwrSply_StrtCurrIp_C
          PA_Rear12VPwrSply_TiKtp_C: accessed-parameter=Rear12VPwrSply_TiKtp_C
          PA_Rear12VPwrSply_TstCurr_C: accessed-parameter=Rear12VPwrSply_TstCurr_C
          PA_RearBlowerPwrSply_OvrCurrThres_C: accessed-parameter=RearBlowerPwrSply_OvrCurrThres_C
          PA_RearBlowerPwrSply_StrtCurrIp_C: accessed-parameter=RearBlowerPwrSply_StrtCurrIp_C
          PA_RearBlowerPwrSply_TiKtp_C: accessed-parameter=RearBlowerPwrSply_TiKtp_C
          PA_RearBlowerPwrSply_TstCurr_C: accessed-parameter=RearBlowerPwrSply_TstCurr_C
          PA_RearCtrlPwrSply_OvrCurrThres_C: accessed-parameter=RearCtrlPwrSply_OvrCurrThres_C
          PA_RearCtrlPwrSply_StrtCurrIp_C: accessed-parameter=RearCtrlPwrSply_StrtCurrIp_C
          PA_RearCtrlPwrSply_TiKtp_C: accessed-parameter=RearCtrlPwrSply_TiKtp_C
          PA_RearCtrlPwrSply_TstCurr_C: accessed-parameter=RearCtrlPwrSply_TstCurr_C
          PA_RearEOPPwrSply_OvrCurrThres_C: accessed-parameter=RearEOPPwrSply_OvrCurrThres_C
          PA_RearEOPPwrSply_StrtCurrIp_C: accessed-parameter=RearEOPPwrSply_StrtCurrIp_C
          PA_RearEOPPwrSply_TiKtp_C: accessed-parameter=RearEOPPwrSply_TiKtp_C
          PA_RearEOPPwrSply_TstCurr_C: accessed-parameter=RearEOPPwrSply_TstCurr_C
          PA_RearMotorPwrSply_OvrCurrThres_C: accessed-parameter=RearMotorPwrSply_OvrCurrThres_C
          PA_RearMotorPwrSply_StrtCurrIp_C: accessed-parameter=RearMotorPwrSply_StrtCurrIp_C
          PA_RearMotorPwrSply_TiKtp_C: accessed-parameter=RearMotorPwrSply_TiKtp_C
          PA_RearMotorPwrSply_TstCurr_C: accessed-parameter=RearMotorPwrSply_TstCurr_C
          PA_RearRadarPwrSply_OvrCurrThres_C: accessed-parameter=RearRadarPwrSply_OvrCurrThres_C
          PA_RearRadarPwrSply_StrtCurrIp_C: accessed-parameter=RearRadarPwrSply_StrtCurrIp_C
          PA_RearRadarPwrSply_TiKtp_C: accessed-parameter=RearRadarPwrSply_TiKtp_C
          PA_RearRadarPwrSply_TstCurr_C: accessed-parameter=RearRadarPwrSply_TstCurr_C
          PA_RLALampCtlUnitPwrSply_OvrCurrThres_C: accessed-parameter=RLALampCtlUnitPwrSply_OvrCurrThres_C
          PA_RLALampCtlUnitPwrSply_StrtCurrIp_C: accessed-parameter=RLALampCtlUnitPwrSply_StrtCurrIp_C
          PA_RLALampCtlUnitPwrSply_TiKtp_C: accessed-parameter=RLALampCtlUnitPwrSply_TiKtp_C
          PA_RLALampCtlUnitPwrSply_TstCurr_C: accessed-parameter=RLALampCtlUnitPwrSply_TstCurr_C
          PA_RLBLampCtlUnitPwrSply_OvrCurrThres_C: accessed-parameter=RLBLampCtlUnitPwrSply_OvrCurrThres_C
          PA_RLBLampCtlUnitPwrSply_StrtCurrIp_C: accessed-parameter=RLBLampCtlUnitPwrSply_StrtCurrIp_C
          PA_RLBLampCtlUnitPwrSply_TiKtp_C: accessed-parameter=RLBLampCtlUnitPwrSply_TiKtp_C
          PA_RLBLampCtlUnitPwrSply_TstCurr_C: accessed-parameter=RLBLampCtlUnitPwrSply_TstCurr_C
          PA_RMPwrSply_OvrCurrThres_C: accessed-parameter=RMPwrSply_OvrCurrThres_C
          PA_RMPwrSply_StrtCurrIp_C: accessed-parameter=RMPwrSply_StrtCurrIp_C
          PA_RMPwrSply_TiKtp_C: accessed-parameter=RMPwrSply_TiKtp_C
          PA_RMPwrSply_TstCurr_C: accessed-parameter=RMPwrSply_TstCurr_C
          PA_RRALampCtlUnitPwrSply_OvrCurrThres_C: accessed-parameter=RRALampCtlUnitPwrSply_OvrCurrThres_C
          PA_RRALampCtlUnitPwrSply_StrtCurrIp_C: accessed-parameter=RRALampCtlUnitPwrSply_StrtCurrIp_C
          PA_RRALampCtlUnitPwrSply_TiKtp_C: accessed-parameter=RRALampCtlUnitPwrSply_TiKtp_C
          PA_RRALampCtlUnitPwrSply_TstCurr_C: accessed-parameter=RRALampCtlUnitPwrSply_TstCurr_C
          PA_RRBLampCtlUnitPwrSply_OvrCurrThres_C: accessed-parameter=RRBLampCtlUnitPwrSply_OvrCurrThres_C
          PA_RRBLampCtlUnitPwrSply_StrtCurrIp_C: accessed-parameter=RRBLampCtlUnitPwrSply_StrtCurrIp_C
          PA_RRBLampCtlUnitPwrSply_TiKtp_C: accessed-parameter=RRBLampCtlUnitPwrSply_TiKtp_C
          PA_RRBLampCtlUnitPwrSply_TstCurr_C: accessed-parameter=RRBLampCtlUnitPwrSply_TstCurr_C
      shared-parameters:
        66 x parameter data prototype, all with sw-addr-method=SwAddrMethods/CALDATA, sw-calibration-access=READ-WRITE, init-value=0:
          AMPPwrSply_OvrCurrThres_C: type=ImplementationDataTypes/uint32
          AMPPwrSply_StrtCurrIp_C: type=ImplementationDataTypes/uint32
          AMPPwrSply_TiKtp_C: type=ImplementationDataTypes/uint16
          AMPPwrSply_TstCurr_C: type=ImplementationDataTypes/uint32
          InverterPwrSply_OvrCurrThres_C: type=ImplementationDataTypes/uint32
          InverterPwrSply_StrtCurrIp_C: type=ImplementationDataTypes/uint32
          InverterPwrSply_TiKtp_C: type=ImplementationDataTypes/uint16
          InverterPwrSply_TstCurr_C: type=ImplementationDataTypes/uint32
          KL15T1PwrSply_OvrCurrThres_C: type=ImplementationDataTypes/uint32
          KL15T1PwrSply_StrtCurrIp_C: type=ImplementationDataTypes/uint32
          KL15T1PwrSply_TiKtp_C: type=ImplementationDataTypes/uint16
          KL15T1PwrSply_TstCurr_C: type=ImplementationDataTypes/uint32
          KL15T2PwrSply_OvrCurrThres_C: type=ImplementationDataTypes/uint32
          KL15T2PwrSply_StrtCurrIp_C: type=ImplementationDataTypes/uint32
          KL15T2PwrSply_TiKtp_C: type=ImplementationDataTypes/uint16
          KL15T2PwrSply_TstCurr_C: type=ImplementationDataTypes/uint32
          PCUPwrSply_OvrCurrThres_C: type=ImplementationDataTypes/uint32
          PCUPwrSply_StrtCurrIp_C: type=ImplementationDataTypes/uint32
          PCUPwrSply_TiKtp_C: type=ImplementationDataTypes/uint16
          PCUPwrSply_TstCurr_C: type=ImplementationDataTypes/uint32
          PwrSply_EnaOvrCurrThres_C: type=ImplementationDataTypes/boolean
          PwrSply_EnaTstCurr_C: type=ImplementationDataTypes/boolean
          Rear12VPwrSply_OvrCurrThres_C: type=ImplementationDataTypes/uint32
          Rear12VPwrSply_StrtCurrIp_C: type=ImplementationDataTypes/uint32
          Rear12VPwrSply_TiKtp_C: type=ImplementationDataTypes/uint16
          Rear12VPwrSply_TstCurr_C: type=ImplementationDataTypes/uint32
          RearBlowerPwrSply_OvrCurrThres_C: type=ImplementationDataTypes/uint32
          RearBlowerPwrSply_StrtCurrIp_C: type=ImplementationDataTypes/uint32
          RearBlowerPwrSply_TiKtp_C: type=ImplementationDataTypes/uint16
          RearBlowerPwrSply_TstCurr_C: type=ImplementationDataTypes/uint32
          RearCtrlPwrSply_OvrCurrThres_C: type=ImplementationDataTypes/uint32
          RearCtrlPwrSply_StrtCurrIp_C: type=ImplementationDataTypes/uint32
          RearCtrlPwrSply_TiKtp_C: type=ImplementationDataTypes/uint16
          RearCtrlPwrSply_TstCurr_C: type=ImplementationDataTypes/uint32
          RearEOPPwrSply_OvrCurrThres_C: type=ImplementationDataTypes/uint32
          RearEOPPwrSply_StrtCurrIp_C: type=ImplementationDataTypes/uint32
          RearEOPPwrSply_TiKtp_C: type=ImplementationDataTypes/uint16
          RearEOPPwrSply_TstCurr_C: type=ImplementationDataTypes/uint32
          RearMotorPwrSply_OvrCurrThres_C: type=ImplementationDataTypes/uint32
          RearMotorPwrSply_StrtCurrIp_C: type=ImplementationDataTypes/uint32
          RearMotorPwrSply_TiKtp_C: type=ImplementationDataTypes/uint16
          RearMotorPwrSply_TstCurr_C: type=ImplementationDataTypes/uint32
          RearRadarPwrSply_OvrCurrThres_C: type=ImplementationDataTypes/uint32
          RearRadarPwrSply_StrtCurrIp_C: type=ImplementationDataTypes/uint32
          RearRadarPwrSply_TiKtp_C: type=ImplementationDataTypes/uint16
          RearRadarPwrSply_TstCurr_C: type=ImplementationDataTypes/uint32
          RLALampCtlUnitPwrSply_OvrCurrThres_C: type=ImplementationDataTypes/uint32
          RLALampCtlUnitPwrSply_StrtCurrIp_C: type=ImplementationDataTypes/uint32
          RLALampCtlUnitPwrSply_TiKtp_C: type=ImplementationDataTypes/uint16
          RLALampCtlUnitPwrSply_TstCurr_C: type=ImplementationDataTypes/uint32
          RLBLampCtlUnitPwrSply_OvrCurrThres_C: type=ImplementationDataTypes/uint32
          RLBLampCtlUnitPwrSply_StrtCurrIp_C: type=ImplementationDataTypes/uint32
          RLBLampCtlUnitPwrSply_TiKtp_C: type=ImplementationDataTypes/uint16
          RLBLampCtlUnitPwrSply_TstCurr_C: type=ImplementationDataTypes/uint32
          RMPwrSply_OvrCurrThres_C: type=ImplementationDataTypes/uint32
          RMPwrSply_StrtCurrIp_C: type=ImplementationDataTypes/uint32
          RMPwrSply_TiKtp_C: type=ImplementationDataTypes/uint16
          RMPwrSply_TstCurr_C: type=ImplementationDataTypes/uint32
          RRALampCtlUnitPwrSply_OvrCurrThres_C: type=ImplementationDataTypes/uint32
          RRALampCtlUnitPwrSply_StrtCurrIp_C: type=ImplementationDataTypes/uint32
          RRALampCtlUnitPwrSply_TiKtp_C: type=ImplementationDataTypes/uint16
          RRALampCtlUnitPwrSply_TstCurr_C: type=ImplementationDataTypes/uint32
          RRBLampCtlUnitPwrSply_OvrCurrThres_C: type=ImplementationDataTypes/uint32
          RRBLampCtlUnitPwrSply_StrtCurrIp_C: type=ImplementationDataTypes/uint32
          RRBLampCtlUnitPwrSply_TiKtp_C: type=ImplementationDataTypes/uint16
          RRBLampCtlUnitPwrSply_TstCurr_C: type=ImplementationDataTypes/uint32
  swc implementation HSDPwrSply_ZCU_DD_imp: behavior=KL15PwrSply_DD_InternalBehavior
    code-descriptors:
      code Default: artifact-descriptors=autosar-engineering-object={short-label=Default, category=SWSRC}
package /UAES/ASW/Units
  unit Curr_A: display-name=A, factor-si-to-unit=1, offset-si-to-unit=0
  unit NoUnit: factor-si-to-unit=1, offset-si-to-unit=0
